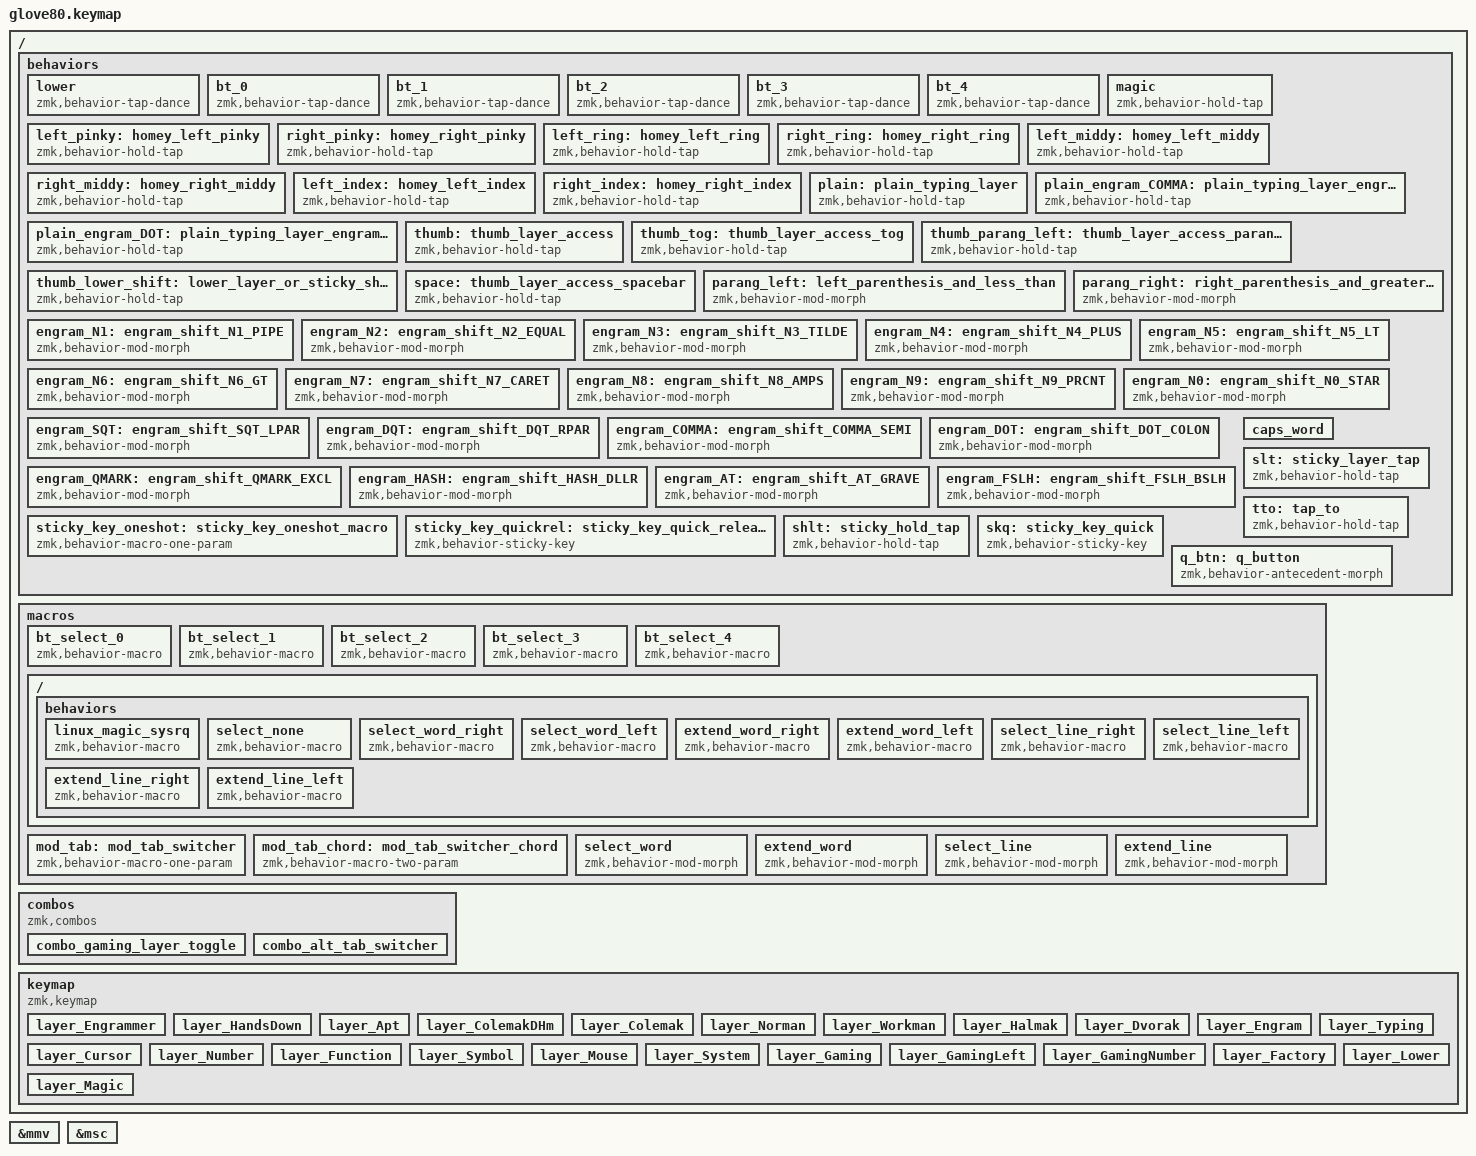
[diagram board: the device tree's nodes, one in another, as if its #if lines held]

/*
 * Copyright (c) 2020 The ZMK Contributors
 * Copyright (c) 2023 Innaworks Development Limited, trading as MoErgo
 *
 * SPDX-License-Identifier: MIT
 */


/* THIS FILE WAS GENERATED BY GLOVE80 LAYOUT EDITOR
 *
 * This file was generated automatically. You may or may not want to
 * edit it directly.
 */

#include <behaviors.dtsi>
/* Include all behavior includes needed */
#include <dt-bindings/zmk/outputs.h>
#include <dt-bindings/zmk/keys.h>
#include <dt-bindings/zmk/bt.h>
#include <dt-bindings/zmk/rgb.h>

/* Automatically generated layer name #define */
#define LAYER_Engrammer 0
#define LAYER_HandsDown 1
#define LAYER_Apt 2
#define LAYER_ColemakDHm 3
#define LAYER_Colemak 4
#define LAYER_Norman 5
#define LAYER_Workman 6
#define LAYER_Halmak 7
#define LAYER_Dvorak 8
#define LAYER_Engram 9
#define LAYER_Typing 10
#define LAYER_Cursor 11
#define LAYER_Number 12
#define LAYER_Function 13
#define LAYER_Symbol 14
#define LAYER_Mouse 15
#define LAYER_System 16
#define LAYER_Gaming 17
#define LAYER_GamingLeft 18
#define LAYER_GamingNumber 19
#define LAYER_Factory 20
#define LAYER_Lower 21
#define LAYER_Magic 22

/* To deal with the situation where there is no Lower layer, to keep &lower happy */
#ifndef LAYER_Lower
#define LAYER_Lower 0
#endif

/* Custom Device-tree */



/* Glove80 system behavior & macros */
/ {
    behaviors {
        // For the "layer" key, it'd nice to be able to use it as either a shift or a toggle.
        // Configure it as a tap dance, so the first tap (or hold) is a &mo and the second tap is a &to
        lower: lower {
            compatible = "zmk,behavior-tap-dance";
            label = "LAYER_TAP_DANCE";
            #binding-cells = <0>;
            tapping-term-ms = <200>;
            bindings = <&mo LAYER_Lower>, <&to LAYER_Lower>;
        };
    };
};

/ {
#ifdef BT_DISC_CMD
    behaviors {
        bt_0: bt_0 {
            compatible = "zmk,behavior-tap-dance";
            label = "BT_0";
            #binding-cells = <0>;
            tapping-term-ms = <200>;
            bindings = <&bt_select_0>, <&bt BT_DISC 0>;
        };
        bt_1: bt_1 {
            compatible = "zmk,behavior-tap-dance";
            label = "BT_1";
            #binding-cells = <0>;
            tapping-term-ms = <200>;
            bindings = <&bt_select_1>, <&bt BT_DISC 1>;
        };
        bt_2: bt_2 {
            compatible = "zmk,behavior-tap-dance";
            label = "BT_2";
            #binding-cells = <0>;
            tapping-term-ms = <200>;
            bindings = <&bt_select_2>, <&bt BT_DISC 2>;
        };
        bt_3: bt_3 {
            compatible = "zmk,behavior-tap-dance";
            label = "BT_3";
            #binding-cells = <0>;
            tapping-term-ms = <200>;
            bindings = <&bt_select_3>, <&bt BT_DISC 3>;
        };
        bt_4: bt_4 {
            compatible = "zmk,behavior-tap-dance";
            label = "BT_4";
            #binding-cells = <0>;
            tapping-term-ms = <200>;
            bindings = <&bt_select_4>, <&bt BT_DISC 4>;
        };
    };
    macros {
        bt_select_0: bt_select_0 {
            label = "BT_SELECT_0";
            compatible = "zmk,behavior-macro";
            #binding-cells = <0>;
            bindings
                = <&out OUT_BLE>,
                  <&bt BT_SEL 0>;
        };
        bt_select_1: bt_select_1 {
            label = "BT_SELECT_1";
            compatible = "zmk,behavior-macro";
            #binding-cells = <0>;
            bindings
                = <&out OUT_BLE>,
                  <&bt BT_SEL 1>;
        };
        bt_select_2: bt_select_2 {
            label = "BT_SELECT_2";
            compatible = "zmk,behavior-macro";
            #binding-cells = <0>;
            bindings
                = <&out OUT_BLE>,
                  <&bt BT_SEL 2>;
        };
        bt_select_3: bt_select_3 {
            label = "BT_SELECT_3";
            compatible = "zmk,behavior-macro";
            #binding-cells = <0>;
            bindings
                = <&out OUT_BLE>,
                  <&bt BT_SEL 3>;
        };
        bt_select_4: bt_select_4 {
            label = "BT_SELECT_4";
            compatible = "zmk,behavior-macro";
            #binding-cells = <0>;
            bindings
                = <&out OUT_BLE>,
                  <&bt BT_SEL 4>;
        };
    };
#else
    macros {
        bt_0: bt_0 {
            label = "BT_0";
            compatible = "zmk,behavior-macro";
            #binding-cells = <0>;
            bindings
                = <&out OUT_BLE>,
                  <&bt BT_SEL 0>;
        };
        bt_1: bt_1 {
            label = "BT_1";
            compatible = "zmk,behavior-macro";
            #binding-cells = <0>;
            bindings
                = <&out OUT_BLE>,
                  <&bt BT_SEL 1>;
        };
        bt_2: bt_2 {
            label = "BT_2";
            compatible = "zmk,behavior-macro";
            #binding-cells = <0>;
            bindings
                = <&out OUT_BLE>,
                  <&bt BT_SEL 2>;
        };
        bt_3: bt_3 {
            label = "BT_3";
            compatible = "zmk,behavior-macro";
            #binding-cells = <0>;
            bindings
                = <&out OUT_BLE>,
                  <&bt BT_SEL 3>;
        };
        bt_4: bt_4 {
            label = "BT_4";
            compatible = "zmk,behavior-macro";
            #binding-cells = <0>;
            bindings
                = <&out OUT_BLE>,
                  <&bt BT_SEL 4>;
        };
    };
#endif
};

/ {
    behaviors {
        magic: magic {
            compatible = "zmk,behavior-hold-tap";
            label = "MAGIC_HOLD_TAP";
            #binding-cells = <2>;
            flavor = "tap-preferred";
            tapping-term-ms = <200>;
            bindings = <&mo>, <&rgb_stat>;
        };
    };
};

/* #define for key positions */
#define POS_LH_T1 52
#define POS_LH_T2 53
#define POS_LH_T3 54
#define POS_LH_T4 69
#define POS_LH_T5 70
#define POS_LH_T6 71
#define POS_LH_C1R2 15
#define POS_LH_C1R3 27
#define POS_LH_C1R4 39
#define POS_LH_C1R5 51
#define POS_LH_C2R1 4
#define POS_LH_C2R2 14
#define POS_LH_C2R3 26
#define POS_LH_C2R4 38
#define POS_LH_C2R5 50
#define POS_LH_C2R6 68
#define POS_LH_C3R1 3
#define POS_LH_C3R2 13
#define POS_LH_C3R3 25
#define POS_LH_C3R4 37
#define POS_LH_C3R5 49
#define POS_LH_C3R6 67
#define POS_LH_C4R1 2
#define POS_LH_C4R2 12
#define POS_LH_C4R3 24
#define POS_LH_C4R4 36
#define POS_LH_C4R5 48
#define POS_LH_C4R6 66
#define POS_LH_C5R1 1
#define POS_LH_C5R2 11
#define POS_LH_C5R3 23
#define POS_LH_C5R4 35
#define POS_LH_C5R5 47
#define POS_LH_C5R6 65
#define POS_LH_C6R1 0
#define POS_LH_C6R2 10
#define POS_LH_C6R3 22
#define POS_LH_C6R4 34
#define POS_LH_C6R5 46
#define POS_LH_C6R6 64
#define POS_RH_T1 57
#define POS_RH_T2 56
#define POS_RH_T3 55
#define POS_RH_T4 74
#define POS_RH_T5 73
#define POS_RH_T6 72
#define POS_RH_C1R2 16
#define POS_RH_C1R3 28
#define POS_RH_C1R4 40
#define POS_RH_C1R5 58
#define POS_RH_C2R1 5
#define POS_RH_C2R2 17
#define POS_RH_C2R3 29
#define POS_RH_C2R4 41
#define POS_RH_C2R5 59
#define POS_RH_C2R6 75
#define POS_RH_C3R1 6
#define POS_RH_C3R2 18
#define POS_RH_C3R3 30
#define POS_RH_C3R4 42
#define POS_RH_C3R5 60
#define POS_RH_C3R6 76
#define POS_RH_C4R1 7
#define POS_RH_C4R2 19
#define POS_RH_C4R3 31
#define POS_RH_C4R4 43
#define POS_RH_C4R5 61
#define POS_RH_C4R6 77
#define POS_RH_C5R1 8
#define POS_RH_C5R2 20
#define POS_RH_C5R3 32
#define POS_RH_C5R4 44
#define POS_RH_C5R5 62
#define POS_RH_C5R6 78
#define POS_RH_C6R1 9
#define POS_RH_C6R2 21
#define POS_RH_C6R3 33
#define POS_RH_C6R4 45
#define POS_RH_C6R5 63
#define POS_RH_C6R6 79

/* Custom Defined Behaviors */
/ {
// Custom settings
//#define OPERATING_SYSTEM 'L' // Linux
//#define OPERATING_SYSTEM 'M' // macOS
#define OPERATING_SYSTEM 'W' // Windows
#define DIFFICULTY_LEVEL  0 // 0:custom, 1:easy -> 5:hard (see below)
//#define WORLD_USE_COMPOSE   // use native Compose in place of Unicode
//#define USE_NUMPAD_KEYCODES // use numpad keys for number layer
#define QU_RESET_TIME 250
#define COMBO_HOLDING_TIME 200
#define LEFT_PINKY_MOD  LGUI
#define RIGHT_PINKY_MOD RGUI
#define LEFT_RING_MOD  LALT
#define RIGHT_RING_MOD RALT
#define LEFT_MIDDY_MOD  LCTL
#define RIGHT_MIDDY_MOD RCTL
#define LEFT_INDEX_MOD  LSFT
#define RIGHT_INDEX_MOD RSFT

// NOTE: Use the `#define` settings below to customize this keymap!
// For example, here are the main optional features you can enable:
//#define DIFFICULTY_LEVEL  0 // 0:custom, 1:easy -> 5:hard (see below)
//#define WORLD_USE_COMPOSE   // use native Compose in place of Unicode
//#define USE_BILATERAL_HOLD_TAPS // use bilateral HRMs in the compiled default keymap
// TIP: Add more setting overrides here instead of editing them below.

//////////////////////////////////////////////////////////////////////////////
//
// Sunaku's Keymap v36 -- "Glorious Engrammer"
// - https://github.com/sunaku/glove80-keymaps
//
//////////////////////////////////////////////////////////////////////////////

//
// DIFFICULTY_LEVEL specifies your level of expertise with this keymap.
// It's meant to help newcomers gradually work their way up to mastery.
// You can disable this setting by omitting it or assigning a `0` zero.
//
// #define DIFFICULTY_LEVEL 0 // custom (see defaults below)
// #define DIFFICULTY_LEVEL 1 // novice (500ms)
// #define DIFFICULTY_LEVEL 2 // slower (400ms)
// #define DIFFICULTY_LEVEL 3 // normal (300ms)
// #define DIFFICULTY_LEVEL 4 // faster (200ms)
// #define DIFFICULTY_LEVEL 5 // expert (100ms)
//
#if defined(DIFFICULTY_LEVEL) && DIFFICULTY_LEVEL > 0
#define DIFFICULTY_LEVEL_HOLDING_TIME  ((6 - DIFFICULTY_LEVEL) * 100)
#define DIFFICULTY_LEVEL_STREAK_DECAY (((6 - DIFFICULTY_LEVEL) *  50) + 100)
#ifndef HOMEY_HOLDING_TIME
#define HOMEY_HOLDING_TIME DIFFICULTY_LEVEL_HOLDING_TIME
#endif
#ifndef HOMEY_STREAK_DECAY
#define HOMEY_STREAK_DECAY DIFFICULTY_LEVEL_STREAK_DECAY
#endif
#ifndef INDEX_HOLDING_TIME
#define INDEX_HOLDING_TIME DIFFICULTY_LEVEL_HOLDING_TIME
#endif
#ifndef INDEX_STREAK_DECAY
#define INDEX_STREAK_DECAY DIFFICULTY_LEVEL_STREAK_DECAY
#endif
#ifndef PLAIN_HOLDING_TIME
#define PLAIN_HOLDING_TIME DIFFICULTY_LEVEL_HOLDING_TIME
#endif
#ifndef PLAIN_STREAK_DECAY
#define PLAIN_STREAK_DECAY DIFFICULTY_LEVEL_STREAK_DECAY
#endif
#ifndef SPACE_HOLDING_TIME
#define SPACE_HOLDING_TIME DIFFICULTY_LEVEL_HOLDING_TIME
#endif
#ifndef SPACE_STREAK_DECAY
#define SPACE_STREAK_DECAY DIFFICULTY_LEVEL_STREAK_DECAY
#endif
#endif

//
// OPERATING_SYSTEM defines which operating system you intend to use
// with this keymap, because shortcuts vary across operating systems.
//
// - https://zmk.dev/docs/codes
// - https://en.wikipedia.org/wiki/Table_of_keyboard_shortcuts
//
#ifndef OPERATING_SYSTEM
//#define OPERATING_SYSTEM 'L' // linux
//#define OPERATING_SYSTEM 'M' // macos
#define OPERATING_SYSTEM 'W' // windows
#endif
#if OPERATING_SYSTEM == 'M'
    #define _C      LG
    #define _A_TAB  LGUI
    #define _G_TAB  LALT
    #define _REDO   _C(LS(Z))
    #define _W      LA
    #define _HOME   _C(LEFT)
    #define _END    _C(RIGHT)
    #define _LOCK   _C(LC(Q))
    #define _SLEEP  C_SLEEP
    #define _POWER  K_POWER
#else
    #define _C      LC
    #define _A_TAB  LALT
    #define _G_TAB  LGUI
    #define _REDO   _C(Y)
    #define _W      _C
    #define _HOME   HOME
    #define _END    END
    #define _LOCK   LG(L)
    #define _SLEEP  SYS_SLEEP
    #define _POWER  SYS_PWR
#endif
/*
#if OPERATING_SYSTEM == 'W'
    #define _LOCK   LG(L)
    #define _SLEEP  SYS_SLEEP
    #define _POWER  SYS_PWR
#elif OPERATING_SYSTEM == 'M'
    #define _LOCK   _C(LC(Q))
    #define _SLEEP  C_SLEEP
    #define _POWER  K_POWER
#elif OPERATING_SYSTEM == 'L'
    #define _LOCK   LG(L)
    #define _SLEEP  C_SLEEP
    #define _POWER  C_POWER
#endif
*/
#define _UNDO       _C(Z)
#define _CUT        _C(X)
#define _COPY       _C(C)
#define _PASTE      _C(V)
#define _FIND       _C(F)
#define _FIND_NEXT  _C(G)
#define _FIND_PREV  _C(LS(G))
#define SLEEP  kp _SLEEP
#define POWER  kp _POWER

//
// USE_NUMPAD_KEYCODES puts `KP_*` keycodes into the Number layer.
//
#ifdef USE_NUMPAD_KEYCODES
#define _KP_N0 KP_N0
#define _KP_N1 KP_N1
#define _KP_N2 KP_N2
#define _KP_N3 KP_N3
#define _KP_N4 KP_N4
#define _KP_N5 KP_N5
#define _KP_N6 KP_N6
#define _KP_N7 KP_N7
#define _KP_N8 KP_N8
#define _KP_N9 KP_N9
#define _KP_PLUS KP_PLUS
#define _KP_MINUS KP_MINUS
#define _KP_ASTERISK KP_ASTERISK
#define _KP_SLASH KP_SLASH
#define _KP_COMMA KP_COMMA
#define _KP_DOT KP_DOT
#define _KP_EQUAL KP_EQUAL
#define _KP_ENTER KP_ENTER
#else
#define _KP_N0 N0
#define _KP_N1 N1
#define _KP_N2 N2
#define _KP_N3 N3
#define _KP_N4 N4
#define _KP_N5 N5
#define _KP_N6 N6
#define _KP_N7 N7
#define _KP_N8 N8
#define _KP_N9 N9
#define _KP_PLUS PLUS
#define _KP_MINUS MINUS
#define _KP_ASTERISK ASTERISK
#define _KP_SLASH SLASH
#define _KP_COMMA COMMA
#define _KP_DOT DOT
#define _KP_EQUAL EQUAL
#define _KP_ENTER ENTER
#endif

//
// Glove80 specific symbol overrides to support non "en-US" locales
//
#undef  AMPS
#define AMPS  LS(N7)
#undef  AT
#define AT    LS(N2)
#undef  CARET
#define CARET LS(N6)
#undef  COLON
#define COLON LS(SEMI)
#undef  DLLR
#define DLLR  LS(N4)
#undef  DQT
#define DQT   LS(SQT)
#undef  EXCL
#define EXCL  LS(N1)
#undef  GT
#define GT    LS(DOT)
#undef  HASH
#define HASH  LS(N3)
#undef  LBRC
#define LBRC  LS(LBKT)
#undef  LPAR
#define LPAR  LS(N9)
#undef  LT
#define LT    LS(COMMA)
#undef  PIPE
#define PIPE  LS(BSLH)
#undef  PLUS
#define PLUS  LS(EQUAL)
#undef  PRCNT
#define PRCNT LS(N5)
#undef  QMARK
#define QMARK LS(FSLH)
#undef  RBRC
#define RBRC  LS(RBKT)
#undef  RPAR
#define RPAR  LS(N0)
#undef  STAR
#define STAR  LS(N8)
#undef  TILDE
#define TILDE LS(GRAVE)
#undef  UNDER
#define UNDER LS(MINUS)

//
// Keymap specific knowledge of the base layer's alpha + ZMK layout
//
#if defined(LAYER_Engrammer) && LAYER_Engrammer == 0
#define KEY_LH_C6R1 F1
#define KEY_LH_C5R1 F2
#define KEY_LH_C4R1 F3
#define KEY_LH_C3R1 F4
#define KEY_LH_C2R1 F5
#define KEY_RH_C2R1 F6
#define KEY_RH_C3R1 F7
#define KEY_RH_C4R1 F8
#define KEY_RH_C5R1 F9
#define KEY_RH_C6R1 F10
#define KEY_LH_C6R2 GRAVE
#define KEY_LH_C5R2 N1
#define KEY_LH_C4R2 N2
#define KEY_LH_C3R2 N3
#define KEY_LH_C2R2 N4
#define KEY_LH_C1R2 N5
#define KEY_RH_C1R2 N6
#define KEY_RH_C2R2 N7
#define KEY_RH_C3R2 N8
#define KEY_RH_C4R2 N9
#define KEY_RH_C5R2 N0
#define KEY_RH_C6R2 BSLH
#define KEY_LH_C6R3 EQUAL
#define KEY_LH_C5R3 B
#define KEY_LH_C4R3 Y
#define KEY_LH_C3R3 O
#define KEY_LH_C2R3 U
#define KEY_LH_C1R3 SQT
#define KEY_RH_C1R3 SEMI
#define KEY_RH_C2R3 L
#define KEY_RH_C3R3 D
#define KEY_RH_C4R3 W
#define KEY_RH_C5R3 V
#define KEY_RH_C6R3 Z
#define KEY_LH_C6R4 0
#define KEY_LH_C5R4 C
#define KEY_LH_C4R4 I
#define KEY_LH_C3R4 E
#define KEY_LH_C2R4 A
#define KEY_LH_C1R4 COMMA
#define KEY_RH_C1R4 DOT
#define KEY_RH_C2R4 H
#define KEY_RH_C3R4 T
#define KEY_RH_C4R4 S
#define KEY_RH_C5R4 N
#define KEY_RH_C6R4 Q
#define KEY_LH_C6R5 LSHFT
#define KEY_LH_C5R5 G
#define KEY_LH_C4R5 X
#define KEY_LH_C3R5 J
#define KEY_LH_C2R5 K
#define KEY_LH_C1R5 MINUS
#define KEY_LH_T1 ESC
#define KEY_LH_T2 UP
#define KEY_LH_T3 DOWN
#define KEY_RH_T3 LEFT
#define KEY_RH_T2 RIGHT
#define KEY_RH_T1 ENTER
#define KEY_RH_C1R5 FSLH
#define KEY_RH_C2R5 R
#define KEY_RH_C3R5 M
#define KEY_RH_C4R5 F
#define KEY_RH_C5R5 P
#define KEY_RH_C6R5 RSHFT
#define KEY_LH_C6R6 0
#define KEY_LH_C5R6 HOME
#define KEY_LH_C4R6 PG_UP
#define KEY_LH_C3R6 PG_DN
#define KEY_LH_C2R6 END
#define KEY_LH_T4 BACKSPACE
#define KEY_LH_T5 LSFT
#define KEY_LH_T6 DELETE
#define KEY_RH_T6 TAB
#define KEY_RH_T5 RSFT
#define KEY_RH_T4 SPACE
#define KEY_RH_C2R6 LPAR
#define KEY_RH_C3R6 LBKT
#define KEY_RH_C4R6 RBKT
#define KEY_RH_C5R6 RPAR
#define KEY_RH_C6R6 0
#endif
#if defined(LAYER_Engram) && LAYER_Engram == 0
#define KEY_LH_C6R1 F1
#define KEY_LH_C5R1 F2
#define KEY_LH_C4R1 F3
#define KEY_LH_C3R1 F4
#define KEY_LH_C2R1 F5
#define KEY_RH_C2R1 F6
#define KEY_RH_C3R1 F7
#define KEY_RH_C4R1 F8
#define KEY_RH_C5R1 F9
#define KEY_RH_C6R1 F10
#define KEY_LH_C6R2 LBKT
#define KEY_LH_C5R2 N1
#define KEY_LH_C4R2 N2
#define KEY_LH_C3R2 N3
#define KEY_LH_C2R2 N4
#define KEY_LH_C1R2 N5
#define KEY_RH_C1R2 N6
#define KEY_RH_C2R2 N7
#define KEY_RH_C3R2 N8
#define KEY_RH_C4R2 N9
#define KEY_RH_C5R2 N0
#define KEY_RH_C6R2 RBKT
#define KEY_LH_C6R3 AT
#define KEY_LH_C5R3 B
#define KEY_LH_C4R3 Y
#define KEY_LH_C3R3 O
#define KEY_LH_C2R3 U
#define KEY_LH_C1R3 SQT
#define KEY_RH_C1R3 DQT
#define KEY_RH_C2R3 L
#define KEY_RH_C3R3 D
#define KEY_RH_C4R3 W
#define KEY_RH_C5R3 V
#define KEY_RH_C6R3 Z
#define KEY_LH_C6R4 0
#define KEY_LH_C5R4 C
#define KEY_LH_C4R4 I
#define KEY_LH_C3R4 E
#define KEY_LH_C2R4 A
#define KEY_LH_C1R4 COMMA
#define KEY_RH_C1R4 DOT
#define KEY_RH_C2R4 H
#define KEY_RH_C3R4 T
#define KEY_RH_C4R4 S
#define KEY_RH_C5R4 N
#define KEY_RH_C6R4 Q
#define KEY_LH_C6R5 LSHFT
#define KEY_LH_C5R5 G
#define KEY_LH_C4R5 X
#define KEY_LH_C3R5 J
#define KEY_LH_C2R5 K
#define KEY_LH_C1R5 MINUS
#define KEY_LH_T1 ESC
#define KEY_LH_T2 UP
#define KEY_LH_T3 DOWN
#define KEY_RH_T3 LEFT
#define KEY_RH_T2 RIGHT
#define KEY_RH_T1 ENTER
#define KEY_RH_C1R5 QMARK
#define KEY_RH_C2R5 R
#define KEY_RH_C3R5 M
#define KEY_RH_C4R5 F
#define KEY_RH_C5R5 P
#define KEY_RH_C6R5 RSHFT
#define KEY_LH_C6R6 0
#define KEY_LH_C5R6 HOME
#define KEY_LH_C4R6 PG_UP
#define KEY_LH_C3R6 PG_DN
#define KEY_LH_C2R6 END
#define KEY_LH_T4 BACKSPACE
#define KEY_LH_T5 LSFT
#define KEY_LH_T6 DELETE
#define KEY_RH_T6 TAB
#define KEY_RH_T5 RSFT
#define KEY_RH_T4 SPACE
#define KEY_RH_C2R6 LPAR
#define KEY_RH_C3R6 HASH
#define KEY_RH_C4R6 FSLH
#define KEY_RH_C5R6 RPAR
#define KEY_RH_C6R6 0
#endif
#if defined(LAYER_Dvorak) && LAYER_Dvorak == 0
#define KEY_LH_C6R1 F1
#define KEY_LH_C5R1 F2
#define KEY_LH_C4R1 F3
#define KEY_LH_C3R1 F4
#define KEY_LH_C2R1 F5
#define KEY_RH_C2R1 F6
#define KEY_RH_C3R1 F7
#define KEY_RH_C4R1 F8
#define KEY_RH_C5R1 F9
#define KEY_RH_C6R1 F10
#define KEY_LH_C6R2 GRAVE
#define KEY_LH_C5R2 N1
#define KEY_LH_C4R2 N2
#define KEY_LH_C3R2 N3
#define KEY_LH_C2R2 N4
#define KEY_LH_C1R2 N5
#define KEY_RH_C1R2 N6
#define KEY_RH_C2R2 N7
#define KEY_RH_C3R2 N8
#define KEY_RH_C4R2 N9
#define KEY_RH_C5R2 N0
#define KEY_RH_C6R2 BSLH
#define KEY_LH_C6R3 EQUAL
#define KEY_LH_C5R3 SQT
#define KEY_LH_C4R3 COMMA
#define KEY_LH_C3R3 DOT
#define KEY_LH_C2R3 P
#define KEY_LH_C1R3 Y
#define KEY_RH_C1R3 F
#define KEY_RH_C2R3 G
#define KEY_RH_C3R3 C
#define KEY_RH_C4R3 R
#define KEY_RH_C5R3 L
#define KEY_RH_C6R3 SLASH
#define KEY_LH_C6R4 0
#define KEY_LH_C5R4 A
#define KEY_LH_C4R4 O
#define KEY_LH_C3R4 E
#define KEY_LH_C2R4 U
#define KEY_LH_C1R4 I
#define KEY_RH_C1R4 D
#define KEY_RH_C2R4 H
#define KEY_RH_C3R4 T
#define KEY_RH_C4R4 N
#define KEY_RH_C5R4 S
#define KEY_RH_C6R4 MINUS
#define KEY_LH_C6R5 LSHFT
#define KEY_LH_C5R5 SEMI
#define KEY_LH_C4R5 Q
#define KEY_LH_C3R5 J
#define KEY_LH_C2R5 K
#define KEY_LH_C1R5 X
#define KEY_LH_T1 ESC
#define KEY_LH_T2 UP
#define KEY_LH_T3 DOWN
#define KEY_RH_T3 LEFT
#define KEY_RH_T2 RIGHT
#define KEY_RH_T1 ENTER
#define KEY_RH_C1R5 B
#define KEY_RH_C2R5 M
#define KEY_RH_C3R5 W
#define KEY_RH_C4R5 V
#define KEY_RH_C5R5 Z
#define KEY_RH_C6R5 RSHFT
#define KEY_LH_C6R6 0
#define KEY_LH_C5R6 HOME
#define KEY_LH_C4R6 PG_UP
#define KEY_LH_C3R6 PG_DN
#define KEY_LH_C2R6 END
#define KEY_LH_T4 BACKSPACE
#define KEY_LH_T5 LSFT
#define KEY_LH_T6 DELETE
#define KEY_RH_T6 TAB
#define KEY_RH_T5 RSFT
#define KEY_RH_T4 SPACE
#define KEY_RH_C2R6 LPAR
#define KEY_RH_C3R6 LBKT
#define KEY_RH_C4R6 RBKT
#define KEY_RH_C5R6 RPAR
#define KEY_RH_C6R6 0
#endif
#if defined(LAYER_HandsDown) && LAYER_HandsDown == 0
#define KEY_LH_C6R1 F1
#define KEY_LH_C5R1 F2
#define KEY_LH_C4R1 F3
#define KEY_LH_C3R1 F4
#define KEY_LH_C2R1 F5
#define KEY_RH_C2R1 F6
#define KEY_RH_C3R1 F7
#define KEY_RH_C4R1 F8
#define KEY_RH_C5R1 F9
#define KEY_RH_C6R1 F10
#define KEY_LH_C6R2 GRAVE
#define KEY_LH_C5R2 N1
#define KEY_LH_C4R2 N2
#define KEY_LH_C3R2 N3
#define KEY_LH_C2R2 N4
#define KEY_LH_C1R2 N5
#define KEY_RH_C1R2 N6
#define KEY_RH_C2R2 N7
#define KEY_RH_C3R2 N8
#define KEY_RH_C4R2 N9
#define KEY_RH_C5R2 N0
#define KEY_RH_C6R2 UNDER
#define KEY_LH_C6R3 EQUAL
#define KEY_LH_C5R3 X
#define KEY_LH_C4R3 W
#define KEY_LH_C3R3 M
#define KEY_LH_C2R3 G
#define KEY_LH_C1R3 J
#define KEY_RH_C1R3 POUND
#define KEY_RH_C2R3 DOT
#define KEY_RH_C3R3 FSLH
#define KEY_RH_C4R3 DQT
#define KEY_RH_C5R3 SQT
#define KEY_RH_C6R3 Z
#define KEY_LH_C6R4 CAPS
#define KEY_LH_C5R4 S
#define KEY_LH_C4R4 C
#define KEY_LH_C3R4 N
#define KEY_LH_C2R4 T
#define KEY_LH_C1R4 K
#define KEY_RH_C1R4 COMMA
#define KEY_RH_C2R4 A
#define KEY_RH_C3R4 E
#define KEY_RH_C4R4 I
#define KEY_RH_C5R4 H
#define KEY_RH_C6R4 Q
#define KEY_LH_C6R5 LSHFT
#define KEY_LH_C5R5 B
#define KEY_LH_C4R5 F
#define KEY_LH_C3R5 L
#define KEY_LH_C2R5 D
#define KEY_LH_C1R5 V
#define KEY_LH_T1 ESC
#define KEY_LH_T2 UP
#define KEY_LH_T3 DOWN
#define KEY_RH_T3 LEFT
#define KEY_RH_T2 RIGHT
#define KEY_RH_T1 ENTER
#define KEY_RH_C1R5 MINUS
#define KEY_RH_C2R5 U
#define KEY_RH_C3R5 O
#define KEY_RH_C4R5 Y
#define KEY_RH_C5R5 P
#define KEY_RH_C6R5 RSHFT
#define KEY_LH_C6R6 0
#define KEY_LH_C5R6 HOME
#define KEY_LH_C4R6 PG_UP
#define KEY_LH_C3R6 PG_DN
#define KEY_LH_C2R6 END
#define KEY_LH_T4 BACKSPACE
#define KEY_LH_T5 LSFT
#define KEY_LH_T6 DELETE
#define KEY_RH_T6 TAB
#define KEY_RH_T5 RSFT
#define KEY_RH_T4 SPACE
#define KEY_RH_C2R6 LPAR
#define KEY_RH_C3R6 HASH
#define KEY_RH_C4R6 FSLH
#define KEY_RH_C5R6 RPAR
#define KEY_RH_C6R6 0
#endif
#if defined(LAYER_Apt) && LAYER_Apt == 0
#define KEY_LH_C6R1 F1
#define KEY_LH_C5R1 F2
#define KEY_LH_C4R1 F3
#define KEY_LH_C3R1 F4
#define KEY_LH_C2R1 F5
#define KEY_RH_C2R1 F6
#define KEY_RH_C3R1 F7
#define KEY_RH_C4R1 F8
#define KEY_RH_C5R1 F9
#define KEY_RH_C6R1 F10
#define KEY_LH_C6R2 GRAVE
#define KEY_LH_C5R2 N1
#define KEY_LH_C4R2 N2
#define KEY_LH_C3R2 N3
#define KEY_LH_C2R2 N4
#define KEY_LH_C1R2 N5
#define KEY_RH_C1R2 N6
#define KEY_RH_C2R2 N7
#define KEY_RH_C3R2 N8
#define KEY_RH_C4R2 N9
#define KEY_RH_C5R2 N0
#define KEY_RH_C6R2 BSLH
#define KEY_LH_C6R3 EQUAL
#define KEY_LH_C5R3 W
#define KEY_LH_C4R3 G
#define KEY_LH_C3R3 D
#define KEY_LH_C2R3 F
#define KEY_LH_C1R3 B
#define KEY_RH_C1R3 Q
#define KEY_RH_C2R3 L
#define KEY_RH_C3R3 U
#define KEY_RH_C4R3 O
#define KEY_RH_C5R3 Y
#define KEY_RH_C6R3 MINUS
#define KEY_LH_C6R4 0
#define KEY_LH_C5R4 R
#define KEY_LH_C4R4 S
#define KEY_LH_C3R4 T
#define KEY_LH_C2R4 H
#define KEY_LH_C1R4 K
#define KEY_RH_C1R4 J
#define KEY_RH_C2R4 N
#define KEY_RH_C3R4 E
#define KEY_RH_C4R4 A
#define KEY_RH_C5R4 I
#define KEY_RH_C6R4 SEMI
#define KEY_LH_C6R5 LSHFT
#define KEY_LH_C5R5 X
#define KEY_LH_C4R5 C
#define KEY_LH_C3R5 M
#define KEY_LH_C2R5 P
#define KEY_LH_C1R5 V
#define KEY_LH_T1 ESC
#define KEY_LH_T2 UP
#define KEY_LH_T3 DOWN
#define KEY_RH_T3 LEFT
#define KEY_RH_T2 RIGHT
#define KEY_RH_T1 ENTER
#define KEY_RH_C1R5 Z
#define KEY_RH_C2R5 COMMA
#define KEY_RH_C3R5 DOT
#define KEY_RH_C4R5 SQT
#define KEY_RH_C5R5 FSLH
#define KEY_RH_C6R5 RSHFT
#define KEY_LH_C6R6 0
#define KEY_LH_C5R6 HOME
#define KEY_LH_C4R6 PG_UP
#define KEY_LH_C3R6 PG_DN
#define KEY_LH_C2R6 END
#define KEY_LH_T4 BACKSPACE
#define KEY_LH_T5 LSFT
#define KEY_LH_T6 DELETE
#define KEY_RH_T6 TAB
#define KEY_RH_T5 RSFT
#define KEY_RH_T4 SPACE
#define KEY_RH_C2R6 LPAR
#define KEY_RH_C3R6 LBKT
#define KEY_RH_C4R6 RBKT
#define KEY_RH_C5R6 RPAR
#define KEY_RH_C6R6 0
#endif
#if defined(LAYER_ColemakDHm) && LAYER_ColemakDHm == 0
#define KEY_LH_C6R1 F1
#define KEY_LH_C5R1 F2
#define KEY_LH_C4R1 F3
#define KEY_LH_C3R1 F4
#define KEY_LH_C2R1 F5
#define KEY_RH_C2R1 F6
#define KEY_RH_C3R1 F7
#define KEY_RH_C4R1 F8
#define KEY_RH_C5R1 F9
#define KEY_RH_C6R1 F10
#define KEY_LH_C6R2 GRAVE
#define KEY_LH_C5R2 N1
#define KEY_LH_C4R2 N2
#define KEY_LH_C3R2 N3
#define KEY_LH_C2R2 N4
#define KEY_LH_C1R2 N5
#define KEY_RH_C1R2 N6
#define KEY_RH_C2R2 N7
#define KEY_RH_C3R2 N8
#define KEY_RH_C4R2 N9
#define KEY_RH_C5R2 N0
#define KEY_RH_C6R2 BSLH
#define KEY_LH_C6R3 EQUAL
#define KEY_LH_C5R3 Q
#define KEY_LH_C4R3 W
#define KEY_LH_C3R3 F
#define KEY_LH_C2R3 P
#define KEY_LH_C1R3 B
#define KEY_RH_C1R3 J
#define KEY_RH_C2R3 L
#define KEY_RH_C3R3 U
#define KEY_RH_C4R3 Y
#define KEY_RH_C5R3 SEMI
#define KEY_RH_C6R3 MINUS
#define KEY_LH_C6R4 0
#define KEY_LH_C5R4 A
#define KEY_LH_C4R4 R
#define KEY_LH_C3R4 S
#define KEY_LH_C2R4 T
#define KEY_LH_C1R4 G
#define KEY_RH_C1R4 M
#define KEY_RH_C2R4 N
#define KEY_RH_C3R4 E
#define KEY_RH_C4R4 I
#define KEY_RH_C5R4 O
#define KEY_RH_C6R4 SQT
#define KEY_LH_C6R5 LSHFT
#define KEY_LH_C5R5 Z
#define KEY_LH_C4R5 X
#define KEY_LH_C3R5 C
#define KEY_LH_C2R5 D
#define KEY_LH_C1R5 V
#define KEY_LH_T1 ESC
#define KEY_LH_T2 UP
#define KEY_LH_T3 DOWN
#define KEY_RH_T3 LEFT
#define KEY_RH_T2 RIGHT
#define KEY_RH_T1 ENTER
#define KEY_RH_C1R5 K
#define KEY_RH_C2R5 H
#define KEY_RH_C3R5 COMMA
#define KEY_RH_C4R5 DOT
#define KEY_RH_C5R5 FSLH
#define KEY_RH_C6R5 RSHFT
#define KEY_LH_C6R6 0
#define KEY_LH_C5R6 HOME
#define KEY_LH_C4R6 PG_UP
#define KEY_LH_C3R6 PG_DN
#define KEY_LH_C2R6 END
#define KEY_LH_T4 BACKSPACE
#define KEY_LH_T5 LSFT
#define KEY_LH_T6 DELETE
#define KEY_RH_T6 TAB
#define KEY_RH_T5 RSFT
#define KEY_RH_T4 SPACE
#define KEY_RH_C2R6 LPAR
#define KEY_RH_C3R6 LBKT
#define KEY_RH_C4R6 RBKT
#define KEY_RH_C5R6 RPAR
#define KEY_RH_C6R6 0
#endif
#if defined(LAYER_Colemak) && LAYER_Colemak == 0
#define KEY_LH_C6R1 F1
#define KEY_LH_C5R1 F2
#define KEY_LH_C4R1 F3
#define KEY_LH_C3R1 F4
#define KEY_LH_C2R1 F5
#define KEY_RH_C2R1 F6
#define KEY_RH_C3R1 F7
#define KEY_RH_C4R1 F8
#define KEY_RH_C5R1 F9
#define KEY_RH_C6R1 F10
#define KEY_LH_C6R2 GRAVE
#define KEY_LH_C5R2 N1
#define KEY_LH_C4R2 N2
#define KEY_LH_C3R2 N3
#define KEY_LH_C2R2 N4
#define KEY_LH_C1R2 N5
#define KEY_RH_C1R2 N6
#define KEY_RH_C2R2 N7
#define KEY_RH_C3R2 N8
#define KEY_RH_C4R2 N9
#define KEY_RH_C5R2 N0
#define KEY_RH_C6R2 BSLH
#define KEY_LH_C6R3 EQUAL
#define KEY_LH_C5R3 Q
#define KEY_LH_C4R3 W
#define KEY_LH_C3R3 F
#define KEY_LH_C2R3 P
#define KEY_LH_C1R3 G
#define KEY_RH_C1R3 J
#define KEY_RH_C2R3 L
#define KEY_RH_C3R3 U
#define KEY_RH_C4R3 Y
#define KEY_RH_C5R3 SEMI
#define KEY_RH_C6R3 MINUS
#define KEY_LH_C6R4 0
#define KEY_LH_C5R4 A
#define KEY_LH_C4R4 R
#define KEY_LH_C3R4 S
#define KEY_LH_C2R4 T
#define KEY_LH_C1R4 D
#define KEY_RH_C1R4 H
#define KEY_RH_C2R4 N
#define KEY_RH_C3R4 E
#define KEY_RH_C4R4 I
#define KEY_RH_C5R4 O
#define KEY_RH_C6R4 SQT
#define KEY_LH_C6R5 LSHFT
#define KEY_LH_C5R5 Z
#define KEY_LH_C4R5 X
#define KEY_LH_C3R5 C
#define KEY_LH_C2R5 V
#define KEY_LH_C1R5 B
#define KEY_LH_T1 ESC
#define KEY_LH_T2 UP
#define KEY_LH_T3 DOWN
#define KEY_RH_T3 LEFT
#define KEY_RH_T2 RIGHT
#define KEY_RH_T1 ENTER
#define KEY_RH_C1R5 K
#define KEY_RH_C2R5 M
#define KEY_RH_C3R5 COMMA
#define KEY_RH_C4R5 DOT
#define KEY_RH_C5R5 FSLH
#define KEY_RH_C6R5 RSHFT
#define KEY_LH_C6R6 0
#define KEY_LH_C5R6 HOME
#define KEY_LH_C4R6 PG_UP
#define KEY_LH_C3R6 PG_DN
#define KEY_LH_C2R6 END
#define KEY_LH_T4 BACKSPACE
#define KEY_LH_T5 LSFT
#define KEY_LH_T6 DELETE
#define KEY_RH_T6 TAB
#define KEY_RH_T5 RSFT
#define KEY_RH_T4 SPACE
#define KEY_RH_C2R6 LPAR
#define KEY_RH_C3R6 LBKT
#define KEY_RH_C4R6 RBKT
#define KEY_RH_C5R6 RPAR
#define KEY_RH_C6R6 0
#endif
#if defined(LAYER_QWERTY) && LAYER_QWERTY == 0
#define KEY_LH_C6R1 F1
#define KEY_LH_C5R1 F2
#define KEY_LH_C4R1 F3
#define KEY_LH_C3R1 F4
#define KEY_LH_C2R1 F5
#define KEY_RH_C2R1 F6
#define KEY_RH_C3R1 F7
#define KEY_RH_C4R1 F8
#define KEY_RH_C5R1 F9
#define KEY_RH_C6R1 F10
#define KEY_LH_C6R2 GRAVE
#define KEY_LH_C5R2 N1
#define KEY_LH_C4R2 N2
#define KEY_LH_C3R2 N3
#define KEY_LH_C2R2 N4
#define KEY_LH_C1R2 N5
#define KEY_RH_C1R2 N6
#define KEY_RH_C2R2 N7
#define KEY_RH_C3R2 N8
#define KEY_RH_C4R2 N9
#define KEY_RH_C5R2 N0
#define KEY_RH_C6R2 BSLH
#define KEY_LH_C6R3 EQUAL
#define KEY_LH_C5R3 Q
#define KEY_LH_C4R3 W
#define KEY_LH_C3R3 E
#define KEY_LH_C2R3 R
#define KEY_LH_C1R3 T
#define KEY_RH_C1R3 Y
#define KEY_RH_C2R3 U
#define KEY_RH_C3R3 I
#define KEY_RH_C4R3 O
#define KEY_RH_C5R3 P
#define KEY_RH_C6R3 MINUS
#define KEY_LH_C6R4 0
#define KEY_LH_C5R4 A
#define KEY_LH_C4R4 S
#define KEY_LH_C3R4 D
#define KEY_LH_C2R4 F
#define KEY_LH_C1R4 G
#define KEY_RH_C1R4 H
#define KEY_RH_C2R4 J
#define KEY_RH_C3R4 K
#define KEY_RH_C4R4 L
#define KEY_RH_C5R4 SEMI
#define KEY_RH_C6R4 SQT
#define KEY_LH_C6R5 LSHFT
#define KEY_LH_C5R5 Z
#define KEY_LH_C4R5 X
#define KEY_LH_C3R5 C
#define KEY_LH_C2R5 V
#define KEY_LH_C1R5 B
#define KEY_LH_T1 ESC
#define KEY_LH_T2 UP
#define KEY_LH_T3 DOWN
#define KEY_RH_T3 LEFT
#define KEY_RH_T2 RIGHT
#define KEY_RH_T1 ENTER
#define KEY_RH_C1R5 N
#define KEY_RH_C2R5 M
#define KEY_RH_C3R5 COMMA
#define KEY_RH_C4R5 DOT
#define KEY_RH_C5R5 FSLH
#define KEY_RH_C6R5 RSHFT
#define KEY_LH_C6R6 0
#define KEY_LH_C5R6 HOME
#define KEY_LH_C4R6 PG_UP
#define KEY_LH_C3R6 PG_DN
#define KEY_LH_C2R6 END
#define KEY_LH_T4 BACKSPACE
#define KEY_LH_T5 LSFT
#define KEY_LH_T6 DELETE
#define KEY_RH_T6 TAB
#define KEY_RH_T5 RSFT
#define KEY_RH_T4 SPACE
#define KEY_RH_C2R6 LPAR
#define KEY_RH_C3R6 LBKT
#define KEY_RH_C4R6 RBKT
#define KEY_RH_C5R6 RPAR
#define KEY_RH_C6R6 0
#endif
#if defined(LAYER_Norman) && LAYER_Norman == 0
#define KEY_LH_C6R1 F1
#define KEY_LH_C5R1 F2
#define KEY_LH_C4R1 F3
#define KEY_LH_C3R1 F4
#define KEY_LH_C2R1 F5
#define KEY_RH_C2R1 F6
#define KEY_RH_C3R1 F7
#define KEY_RH_C4R1 F8
#define KEY_RH_C5R1 F9
#define KEY_RH_C6R1 F10
#define KEY_LH_C6R2 GRAVE
#define KEY_LH_C5R2 N1
#define KEY_LH_C4R2 N2
#define KEY_LH_C3R2 N3
#define KEY_LH_C2R2 N4
#define KEY_LH_C1R2 N5
#define KEY_RH_C1R2 N6
#define KEY_RH_C2R2 N7
#define KEY_RH_C3R2 N8
#define KEY_RH_C4R2 N9
#define KEY_RH_C5R2 N0
#define KEY_RH_C6R2 BSLH
#define KEY_LH_C6R3 EQUAL
#define KEY_LH_C5R3 Q
#define KEY_LH_C4R3 W
#define KEY_LH_C3R3 D
#define KEY_LH_C2R3 F
#define KEY_LH_C1R3 K
#define KEY_RH_C1R3 J
#define KEY_RH_C2R3 U
#define KEY_RH_C3R3 R
#define KEY_RH_C4R3 L
#define KEY_RH_C5R3 SEMI
#define KEY_RH_C6R3 MINUS
#define KEY_LH_C6R4 0
#define KEY_LH_C5R4 A
#define KEY_LH_C4R4 S
#define KEY_LH_C3R4 E
#define KEY_LH_C2R4 T
#define KEY_LH_C1R4 G
#define KEY_RH_C1R4 Y
#define KEY_RH_C2R4 N
#define KEY_RH_C3R4 I
#define KEY_RH_C4R4 O
#define KEY_RH_C5R4 H
#define KEY_RH_C6R4 SQT
#define KEY_LH_C6R5 LSHFT
#define KEY_LH_C5R5 Z
#define KEY_LH_C4R5 X
#define KEY_LH_C3R5 C
#define KEY_LH_C2R5 V
#define KEY_LH_C1R5 B
#define KEY_LH_T1 ESC
#define KEY_LH_T2 UP
#define KEY_LH_T3 DOWN
#define KEY_RH_T3 LEFT
#define KEY_RH_T2 RIGHT
#define KEY_RH_T1 ENTER
#define KEY_RH_C1R5 P
#define KEY_RH_C2R5 M
#define KEY_RH_C3R5 COMMA
#define KEY_RH_C4R5 DOT
#define KEY_RH_C5R5 FSLH
#define KEY_RH_C6R5 RSHFT
#define KEY_LH_C6R6 0
#define KEY_LH_C5R6 HOME
#define KEY_LH_C4R6 PG_UP
#define KEY_LH_C3R6 PG_DN
#define KEY_LH_C2R6 END
#define KEY_LH_T4 BACKSPACE
#define KEY_LH_T5 LSFT
#define KEY_LH_T6 DELETE
#define KEY_RH_T6 TAB
#define KEY_RH_T5 RSFT
#define KEY_RH_T4 SPACE
#define KEY_RH_C2R6 LPAR
#define KEY_RH_C3R6 LBKT
#define KEY_RH_C4R6 RBKT
#define KEY_RH_C5R6 RPAR
#define KEY_RH_C6R6 0
#endif
#if defined(LAYER_Workman) && LAYER_Workman == 0
#define KEY_LH_C6R1 F1
#define KEY_LH_C5R1 F2
#define KEY_LH_C4R1 F3
#define KEY_LH_C3R1 F4
#define KEY_LH_C2R1 F5
#define KEY_RH_C2R1 F6
#define KEY_RH_C3R1 F7
#define KEY_RH_C4R1 F8
#define KEY_RH_C5R1 F9
#define KEY_RH_C6R1 F10
#define KEY_LH_C6R2 GRAVE
#define KEY_LH_C5R2 N1
#define KEY_LH_C4R2 N2
#define KEY_LH_C3R2 N3
#define KEY_LH_C2R2 N4
#define KEY_LH_C1R2 N5
#define KEY_RH_C1R2 N6
#define KEY_RH_C2R2 N7
#define KEY_RH_C3R2 N8
#define KEY_RH_C4R2 N9
#define KEY_RH_C5R2 N0
#define KEY_RH_C6R2 BSLH
#define KEY_LH_C6R3 EQUAL
#define KEY_LH_C5R3 Q
#define KEY_LH_C4R3 D
#define KEY_LH_C3R3 R
#define KEY_LH_C2R3 W
#define KEY_LH_C1R3 B
#define KEY_RH_C1R3 J
#define KEY_RH_C2R3 F
#define KEY_RH_C3R3 U
#define KEY_RH_C4R3 P
#define KEY_RH_C5R3 SEMI
#define KEY_RH_C6R3 MINUS
#define KEY_LH_C6R4 0
#define KEY_LH_C5R4 A
#define KEY_LH_C4R4 S
#define KEY_LH_C3R4 H
#define KEY_LH_C2R4 T
#define KEY_LH_C1R4 G
#define KEY_RH_C1R4 Y
#define KEY_RH_C2R4 N
#define KEY_RH_C3R4 E
#define KEY_RH_C4R4 O
#define KEY_RH_C5R4 I
#define KEY_RH_C6R4 SQT
#define KEY_LH_C6R5 LSHFT
#define KEY_LH_C5R5 Z
#define KEY_LH_C4R5 X
#define KEY_LH_C3R5 M
#define KEY_LH_C2R5 C
#define KEY_LH_C1R5 V
#define KEY_LH_T1 ESC
#define KEY_LH_T2 UP
#define KEY_LH_T3 DOWN
#define KEY_RH_T3 LEFT
#define KEY_RH_T2 RIGHT
#define KEY_RH_T1 ENTER
#define KEY_RH_C1R5 K
#define KEY_RH_C2R5 L
#define KEY_RH_C3R5 COMMA
#define KEY_RH_C4R5 DOT
#define KEY_RH_C5R5 FSLH
#define KEY_RH_C6R5 RSHFT
#define KEY_LH_C6R6 0
#define KEY_LH_C5R6 HOME
#define KEY_LH_C4R6 PG_UP
#define KEY_LH_C3R6 PG_DN
#define KEY_LH_C2R6 END
#define KEY_LH_T4 BACKSPACE
#define KEY_LH_T5 LSFT
#define KEY_LH_T6 DELETE
#define KEY_RH_T6 TAB
#define KEY_RH_T5 RSFT
#define KEY_RH_T4 SPACE
#define KEY_RH_C2R6 LPAR
#define KEY_RH_C3R6 LBKT
#define KEY_RH_C4R6 RBKT
#define KEY_RH_C5R6 RPAR
#define KEY_RH_C6R6 0
#endif
#if defined(LAYER_Halmak) && LAYER_Halmak == 0
#define KEY_LH_C6R1 F1
#define KEY_LH_C5R1 F2
#define KEY_LH_C4R1 F3
#define KEY_LH_C3R1 F4
#define KEY_LH_C2R1 F5
#define KEY_RH_C2R1 F6
#define KEY_RH_C3R1 F7
#define KEY_RH_C4R1 F8
#define KEY_RH_C5R1 F9
#define KEY_RH_C6R1 F10
#define KEY_LH_C6R2 GRAVE
#define KEY_LH_C5R2 N1
#define KEY_LH_C4R2 N2
#define KEY_LH_C3R2 N3
#define KEY_LH_C2R2 N4
#define KEY_LH_C1R2 N5
#define KEY_RH_C1R2 N6
#define KEY_RH_C2R2 N7
#define KEY_RH_C3R2 N8
#define KEY_RH_C4R2 N9
#define KEY_RH_C5R2 N0
#define KEY_RH_C6R2 BSLH
#define KEY_LH_C6R3 EQUAL
#define KEY_LH_C5R3 W
#define KEY_LH_C4R3 L
#define KEY_LH_C3R3 R
#define KEY_LH_C2R3 B
#define KEY_LH_C1R3 Z
#define KEY_RH_C1R3 SEMI
#define KEY_RH_C2R3 Q
#define KEY_RH_C3R3 U
#define KEY_RH_C4R3 D
#define KEY_RH_C5R3 J
#define KEY_RH_C6R3 MINUS
#define KEY_LH_C6R4 0
#define KEY_LH_C5R4 S
#define KEY_LH_C4R4 H
#define KEY_LH_C3R4 N
#define KEY_LH_C2R4 T
#define KEY_LH_C1R4 COMMA
#define KEY_RH_C1R4 DOT
#define KEY_RH_C2R4 A
#define KEY_RH_C3R4 E
#define KEY_RH_C4R4 O
#define KEY_RH_C5R4 I
#define KEY_RH_C6R4 SQT
#define KEY_LH_C6R5 LSHFT
#define KEY_LH_C5R5 F
#define KEY_LH_C4R5 M
#define KEY_LH_C3R5 V
#define KEY_LH_C2R5 C
#define KEY_LH_C1R5 FSLH
#define KEY_LH_T1 ESC
#define KEY_LH_T2 UP
#define KEY_LH_T3 DOWN
#define KEY_RH_T3 LEFT
#define KEY_RH_T2 RIGHT
#define KEY_RH_T1 ENTER
#define KEY_RH_C1R5 G
#define KEY_RH_C2R5 P
#define KEY_RH_C3R5 X
#define KEY_RH_C4R5 K
#define KEY_RH_C5R5 Y
#define KEY_RH_C6R5 RSHFT
#define KEY_LH_C6R6 0
#define KEY_LH_C5R6 HOME
#define KEY_LH_C4R6 PG_UP
#define KEY_LH_C3R6 PG_DN
#define KEY_LH_C2R6 END
#define KEY_LH_T4 BACKSPACE
#define KEY_LH_T5 LSFT
#define KEY_LH_T6 DELETE
#define KEY_RH_T6 TAB
#define KEY_RH_T5 RSFT
#define KEY_RH_T4 SPACE
#define KEY_RH_C2R6 LPAR
#define KEY_RH_C3R6 LBKT
#define KEY_RH_C4R6 RBKT
#define KEY_RH_C5R6 RPAR
#define KEY_RH_C6R6 0
#endif

combos {
    compatible = "zmk,combos";

    //
    // COMBO_FIRING_DECAY defines how much time you have left (milliseconds)
    // after pressing the first key in a ZMK combo to finish the whole chord.
    //
    #ifndef COMBO_FIRING_DECAY
    #define COMBO_FIRING_DECAY 50
    #endif
    #ifdef LAYER_Gaming
    combo_gaming_layer_toggle {
        timeout-ms = <COMBO_FIRING_DECAY>;
        key-positions = <POS_LH_T3 POS_LH_T6>;
        bindings = <&tog LAYER_Gaming>;
        layers = <0 LAYER_Gaming>;
    };
    #endif
    #ifdef _A_TAB
    combo_alt_tab_switcher {
        timeout-ms = <COMBO_FIRING_DECAY>;
        key-positions = <POS_LH_T4 POS_LH_T1>;
        bindings = <&mod_tab_chord _A_TAB LAYER_Cursor>;
        layers = <0 1 2 3 4 5 6 7 8>;
    };
    #endif
};

behaviors {

    //////////////////////////////////////////////////////////////////////////
    //
    // Miryoku layers and home row mods (ported from my QMK endgame)
    // - https://sunaku.github.io/home-row-mods.html#porting-to-zmk
    // - https://github.com/urob/zmk-config#timeless-homerow-mods
    //
    //////////////////////////////////////////////////////////////////////////

    //
    // The *_FINGER_MOD specify which modifiers are used by home row mod keys.
    // Here, we use Miryoku's "GACS" (Win, Alt, Ctrl, Shift) order by default,
    // unless OPERATING_SYSTEM is macOS, in which case Win & Ctrl are swapped.
    //
    #ifndef PINKY_FINGER_MOD
      #if OPERATING_SYSTEM == 'M'
        #define PINKY_FINGER_MOD LCTL
      #else
        #define PINKY_FINGER_MOD LGUI
      #endif
    #endif
    #ifndef RING_FINGER_MOD
    #define RING_FINGER_MOD LALT
    #endif
    #ifndef MIDDY_FINGER_MOD
      #if OPERATING_SYSTEM == 'M'
        #define MIDDY_FINGER_MOD LGUI
      #else
        #define MIDDY_FINGER_MOD LCTL
      #endif
    #endif
    #ifndef INDEX_FINGER_MOD
    #define INDEX_FINGER_MOD LSFT
    #endif
    //
    // The following settings let you configure mods individually, per finger:
    //
    #ifndef LEFT_PINKY_MOD
    #define LEFT_PINKY_MOD  PINKY_FINGER_MOD
    #endif
    #ifndef RIGHT_PINKY_MOD
    #define RIGHT_PINKY_MOD PINKY_FINGER_MOD
    #endif
    #ifndef LEFT_RING_MOD
    #define LEFT_RING_MOD  RING_FINGER_MOD
    #endif
    #ifndef RIGHT_RING_MOD
    #define RIGHT_RING_MOD RING_FINGER_MOD
    #endif
    #ifndef LEFT_MIDDY_MOD
    #define LEFT_MIDDY_MOD  MIDDY_FINGER_MOD
    #endif
    #ifndef RIGHT_MIDDY_MOD
    #define RIGHT_MIDDY_MOD MIDDY_FINGER_MOD
    #endif
    #ifndef LEFT_INDEX_MOD
    #define LEFT_INDEX_MOD  INDEX_FINGER_MOD
    #endif
    #ifndef RIGHT_INDEX_MOD
    #define RIGHT_INDEX_MOD INDEX_FINGER_MOD
    #endif

    //
    // HOMEY_HOLDING_TYPE defines the flavor of ZMK hold-tap behavior to use
    // for the pinky, ring, and middle fingers (which are assigned to Super,
    // Alt, and Ctrl respectively in the Miryoku system) on home row keys.
    //
    #ifndef HOMEY_HOLDING_TYPE
    #define HOMEY_HOLDING_TYPE "tap-preferred"
    #endif

    //
    // HOMEY_HOLDING_TIME defines how long you need to hold (milliseconds)
    // home row mod keys in order to send their modifiers to the computer
    // (i.e. "register" them) for mod-click mouse usage (e.g. Ctrl-Click).
    //
    #ifndef HOMEY_HOLDING_TIME
    #define HOMEY_HOLDING_TIME 240 // TAPPING_TERM + ALLOW_CROSSOVER_AFTER
    #endif

    //
    // HOMEY_STREAK_DECAY defines how long you need to wait (milliseconds)
    // after typing before you can use home row mods again.  It prevents
    // unintended activation of home row mods when you're actively typing.
    //
    #ifndef HOMEY_STREAK_DECAY
    #define HOMEY_STREAK_DECAY 160
    #endif

    //
    // HOMEY_REPEAT_DECAY defines how much time you have left (milliseconds)
    // after tapping a key to hold it again in order to make it auto-repeat.
    //
    #ifndef HOMEY_REPEAT_DECAY
    #define HOMEY_REPEAT_DECAY 300 // "tap then hold" for key auto-repeat
    #endif

    //
    // INDEX_HOLDING_TYPE defines the flavor of ZMK hold-tap behavior to use
    // for index fingers (which Miryoku assigns to Shift) on home row keys.
    //
    // NOTE: The "tap-preferred" flavor of ZMK hold-tap for index finger keys
    // allows faster activation of the Shift modifier (without having to wait
    // for the modified key to be released as the "balanced" flavor requires).
    // Typing streaks and the `hold-trigger-on-release` setting are disabled
    // for the index fingers so as not to hinder their speed and dexterity.
    //
    #ifndef INDEX_HOLDING_TYPE
    #define INDEX_HOLDING_TYPE "tap-preferred"
    #endif

    //
    // INDEX_HOLDING_TIME defines how long you need to hold (milliseconds)
    // index finger keys in order to send their modifiers to the computer
    // (i.e. "register" them) for mod-click mouse usage (e.g. Shift-Click).
    //
    #ifndef INDEX_HOLDING_TIME
    #define INDEX_HOLDING_TIME 180
    #endif

    //
    // INDEX_STREAK_DECAY defines how long you need to wait (milliseconds)
    // after typing before you can use home row mods again.  It prevents
    // unintended activation of home row mods when you're actively typing.
    //
    #ifndef INDEX_STREAK_DECAY
    #define INDEX_STREAK_DECAY 100
    #endif

    //
    // INDEX_REPEAT_DECAY defines how much time you have left (milliseconds)
    // after tapping a key to hold it again in order to make it auto-repeat.
    //
    #ifndef INDEX_REPEAT_DECAY
    #define INDEX_REPEAT_DECAY 300 // "tap then hold" for key auto-repeat
    #endif

    //
    // PLAIN_HOLDING_TYPE defines the flavor of ZMK hold-tap behavior to use
    // for index fingers (which Miryoku assigns to Shift) on home row keys.
    //
    // NOTE: The "tap-preferred" flavor of ZMK hold-tap for index finger keys
    // allows faster activation of the Shift modifier (without having to wait
    // for the modified key to be released as the "balanced" flavor requires).
    // Typing streaks and the `hold-trigger-on-release` setting are disabled
    // for the index fingers so as not to hinder their speed and dexterity.
    //
    #ifndef PLAIN_HOLDING_TYPE
    #define PLAIN_HOLDING_TYPE HOMEY_HOLDING_TYPE
    #endif

    //
    // PLAIN_HOLDING_TIME defines how long you need to hold (milliseconds)
    // index finger keys in order to send their modifiers to the computer
    // (i.e. "register" them) for mod-click mouse usage (e.g. Shift-Click).
    //
    #ifndef PLAIN_HOLDING_TIME
    #define PLAIN_HOLDING_TIME HOMEY_HOLDING_TIME
    #endif

    //
    // PLAIN_STREAK_DECAY defines how long you need to wait (milliseconds)
    // after typing before you can use home row mods again.  It prevents
    // unintended activation of home row mods when you're actively typing.
    //
    #ifndef PLAIN_STREAK_DECAY
    #define PLAIN_STREAK_DECAY HOMEY_STREAK_DECAY
    #endif

    //
    // PLAIN_REPEAT_DECAY defines how much time you have left (milliseconds)
    // after tapping a key to hold it again in order to make it auto-repeat.
    //
    #ifndef PLAIN_REPEAT_DECAY
    #define PLAIN_REPEAT_DECAY 300 // "tap then hold" for key auto-repeat
    #endif

    //
    // THUMB_HOLDING_TYPE defines the flavor of ZMK hold-tap behavior to use
    // for the thumbs (which are assigned to 6 layers in the Miryoku system).
    //
    // NOTE: The "balanced" flavor of ZMK hold-tap provides instant modifier
    // activation for the symbol layer (if the tapped symbol key is released
    // while the thumb layer key is still held down) for quicker programming.
    //
    #ifndef THUMB_HOLDING_TYPE
    #define THUMB_HOLDING_TYPE "balanced"
    #endif

    //
    // THUMB_HOLDING_TIME defines how long you need to hold (milliseconds)
    // a thumb key to activate a layer.  Shorter holds are treated as taps.
    //
    #ifndef THUMB_HOLDING_TIME
    #define THUMB_HOLDING_TIME 200
    #endif

    //
    // THUMB_REPEAT_DECAY defines how much time you have left (milliseconds)
    // after tapping a key to hold it again in order to make it auto-repeat.
    //
    #ifndef THUMB_REPEAT_DECAY
    #define THUMB_REPEAT_DECAY 300 // "tap then hold" for key auto-repeat
    #endif

    //
    // SPACE_HOLDING_TYPE defines the flavor of ZMK hold-tap behavior to use
    // for spacebar (assigned to the right thumb's home position by default).
    //
    // NOTE: The "balanced" flavor of ZMK hold-tap provides instant modifier
    // activation for the symbol layer (if the tapped symbol key is released
    // while the thumb layer key is still held down) for quicker programming.
    //
    #ifndef SPACE_HOLDING_TYPE
    #define SPACE_HOLDING_TYPE THUMB_HOLDING_TYPE
    #endif

    //
    // SPACE_HOLDING_TIME defines how long you need to hold (milliseconds)
    // the space thumb key to activate.  Shorter holds are treated as taps.
    //
    #ifndef SPACE_HOLDING_TIME
    #define SPACE_HOLDING_TIME THUMB_HOLDING_TIME
    #endif

    //
    // SPACE_REPEAT_DECAY defines how much time you have left (milliseconds)
    // after tapping a key to hold it again in order to make it auto-repeat.
    //
    #ifndef SPACE_REPEAT_DECAY
    #define SPACE_REPEAT_DECAY 150
    #endif

    //
    // Glove80 key positions index for positional hold-tap
    // - https://discord.com/channels/877392805654306816/937645688244826154/1066713913351221248
    // - https://media.discordapp.net/attachments/937645688244826154/1066713913133121556/image.png
    //
    // |------------------------|------------------------|
    // | LEFT_HAND_KEYS         |        RIGHT_HAND_KEYS |
    // |                        |                        |
    // |  0  1  2  3  4         |          5  6  7  8  9 |
    // | 10 11 12 13 14 15      |      16 17 18 19 20 21 |
    // | 22 23 24 25 26 27      |      28 29 30 31 32 33 |
    // | 34 35 36 37 38 39      |      40 41 42 43 44 45 |
    // | 46 47 48 49 50 51      |      58 59 60 61 62 63 |
    // | 64 65 66 67 68         |         75 76 77 78 79 |
    // |                69 52   |   57 74                |
    // |                 70 53  |  56 73                 |
    // |                  71 54 | 55 72                  |
    // |------------------------|------------------------|
    //
    #define LEFT_HAND_KEYS      \
          0  1  2  3  4         \
         10 11 12 13 14 15      \
         22 23 24 25 26 27      \
         34 35 36 37 38 39      \
         46 47 48 49 50 51      \
         64 65 66 67 68
    #define RIGHT_HAND_KEYS     \
                                           5  6  7  8  9 \
                                       16 17 18 19 20 21 \
                                       28 29 30 31 32 33 \
                                       40 41 42 43 44 45 \
                                       58 59 60 61 62 63 \
                                          75 76 77 78 79
    #define THUMB_KEYS          \
                        69 52       57 74                \
                         70 53     56 73                 \
                          71 54   55 72

    #define LEFT_PINKY_KEY  KEY_LH_C5R4
    #define LEFT_RING_KEY  KEY_LH_C4R4
    #define LEFT_MIDDY_KEY  KEY_LH_C3R4
    #define LEFT_INDEX_KEY  KEY_LH_C2R4
    #define LEFT_PLAIN_KEY  KEY_LH_C1R4

    #define RIGHT_PINKY_KEY KEY_RH_C5R4
    #define RIGHT_RING_KEY KEY_RH_C4R4
    #define RIGHT_MIDDY_KEY KEY_RH_C3R4
    #define RIGHT_INDEX_KEY KEY_RH_C2R4
    #define RIGHT_PLAIN_KEY KEY_RH_C1R4
    #if defined(LAYER_Engram) && LAYER_Engram == 0
    #define LeftPlainKey  engram_COMMA
    #define RightPlainKey engram_DOT
    #else
    #define LeftPlainKey  kp LEFT_PLAIN_KEY
    #define RightPlainKey kp RIGHT_PLAIN_KEY
    #endif

    //
    // Studio-editable home-row modifiers
    //
    // Bilateral enforcement is selected at compile time without duplicating
    // the per-finger behavior nodes or their Studio metadata.
    //
#define HOME_ROW_MOD(name) &name

#ifndef HRM_LINGER_TIME
#define HRM_LINGER_TIME 100
#endif

#ifndef LEFT_PINKY_HOLDING_TYPE
#define LEFT_PINKY_HOLDING_TYPE HOMEY_HOLDING_TYPE
#endif
#ifndef LEFT_PINKY_HOLDING_TIME
#define LEFT_PINKY_HOLDING_TIME HOMEY_HOLDING_TIME
#endif
#ifndef LEFT_PINKY_STREAK_DECAY
#define LEFT_PINKY_STREAK_DECAY HOMEY_STREAK_DECAY
#endif
#ifndef LEFT_PINKY_REPEAT_DECAY
#define LEFT_PINKY_REPEAT_DECAY HOMEY_REPEAT_DECAY
#endif
    left_pinky: homey_left_pinky {
        compatible = "zmk,behavior-hold-tap";
        display-name = "Left Pinky HRM";
        flavor = LEFT_PINKY_HOLDING_TYPE;
        hold-trigger-key-positions = <RIGHT_HAND_KEYS THUMB_KEYS>;
        hold-trigger-on-release;
#ifdef USE_BILATERAL_HOLD_TAPS
        enforce-bilateral;
#endif // USE_BILATERAL_HOLD_TAPS
        linger-ms = <HRM_LINGER_TIME>;
        tapping-term-ms = <LEFT_PINKY_HOLDING_TIME>;
        quick-tap-ms = <LEFT_PINKY_REPEAT_DECAY>;
        require-prior-idle-ms = <LEFT_PINKY_STREAK_DECAY>;
        #binding-cells = <2>;
        bindings = <&kp>, <&kp>;
    };
#ifndef RIGHT_PINKY_HOLDING_TYPE
#define RIGHT_PINKY_HOLDING_TYPE HOMEY_HOLDING_TYPE
#endif
#ifndef RIGHT_PINKY_HOLDING_TIME
#define RIGHT_PINKY_HOLDING_TIME HOMEY_HOLDING_TIME
#endif
#ifndef RIGHT_PINKY_STREAK_DECAY
#define RIGHT_PINKY_STREAK_DECAY HOMEY_STREAK_DECAY
#endif
#ifndef RIGHT_PINKY_REPEAT_DECAY
#define RIGHT_PINKY_REPEAT_DECAY HOMEY_REPEAT_DECAY
#endif
    right_pinky: homey_right_pinky {
        compatible = "zmk,behavior-hold-tap";
        display-name = "Right Pinky HRM";
        flavor = RIGHT_PINKY_HOLDING_TYPE;
        hold-trigger-key-positions = <LEFT_HAND_KEYS THUMB_KEYS>;
        hold-trigger-on-release;
#ifdef USE_BILATERAL_HOLD_TAPS
        enforce-bilateral;
#endif // USE_BILATERAL_HOLD_TAPS
        linger-ms = <HRM_LINGER_TIME>;
        tapping-term-ms = <RIGHT_PINKY_HOLDING_TIME>;
        quick-tap-ms = <RIGHT_PINKY_REPEAT_DECAY>;
        require-prior-idle-ms = <RIGHT_PINKY_STREAK_DECAY>;
        #binding-cells = <2>;
        bindings = <&kp>, <&kp>;
    };
#ifndef LEFT_RING_HOLDING_TYPE
#define LEFT_RING_HOLDING_TYPE HOMEY_HOLDING_TYPE
#endif
#ifndef LEFT_RING_HOLDING_TIME
#define LEFT_RING_HOLDING_TIME HOMEY_HOLDING_TIME
#endif
#ifndef LEFT_RING_STREAK_DECAY
#define LEFT_RING_STREAK_DECAY HOMEY_STREAK_DECAY
#endif
#ifndef LEFT_RING_REPEAT_DECAY
#define LEFT_RING_REPEAT_DECAY HOMEY_REPEAT_DECAY
#endif
    left_ring: homey_left_ring {
        compatible = "zmk,behavior-hold-tap";
        display-name = "Left Ring HRM";
        flavor = LEFT_RING_HOLDING_TYPE;
        hold-trigger-key-positions = <RIGHT_HAND_KEYS THUMB_KEYS>;
        hold-trigger-on-release;
#ifdef USE_BILATERAL_HOLD_TAPS
        enforce-bilateral;
#endif // USE_BILATERAL_HOLD_TAPS
        linger-ms = <HRM_LINGER_TIME>;
        tapping-term-ms = <LEFT_RING_HOLDING_TIME>;
        quick-tap-ms = <LEFT_RING_REPEAT_DECAY>;
        require-prior-idle-ms = <LEFT_RING_STREAK_DECAY>;
        #binding-cells = <2>;
        bindings = <&kp>, <&kp>;
    };
#ifndef RIGHT_RING_HOLDING_TYPE
#define RIGHT_RING_HOLDING_TYPE HOMEY_HOLDING_TYPE
#endif
#ifndef RIGHT_RING_HOLDING_TIME
#define RIGHT_RING_HOLDING_TIME HOMEY_HOLDING_TIME
#endif
#ifndef RIGHT_RING_STREAK_DECAY
#define RIGHT_RING_STREAK_DECAY HOMEY_STREAK_DECAY
#endif
#ifndef RIGHT_RING_REPEAT_DECAY
#define RIGHT_RING_REPEAT_DECAY HOMEY_REPEAT_DECAY
#endif
    right_ring: homey_right_ring {
        compatible = "zmk,behavior-hold-tap";
        display-name = "Right Ring HRM";
        flavor = RIGHT_RING_HOLDING_TYPE;
        hold-trigger-key-positions = <LEFT_HAND_KEYS THUMB_KEYS>;
        hold-trigger-on-release;
#ifdef USE_BILATERAL_HOLD_TAPS
        enforce-bilateral;
#endif // USE_BILATERAL_HOLD_TAPS
        linger-ms = <HRM_LINGER_TIME>;
        tapping-term-ms = <RIGHT_RING_HOLDING_TIME>;
        quick-tap-ms = <RIGHT_RING_REPEAT_DECAY>;
        require-prior-idle-ms = <RIGHT_RING_STREAK_DECAY>;
        #binding-cells = <2>;
        bindings = <&kp>, <&kp>;
    };
#ifndef LEFT_MIDDY_HOLDING_TYPE
#define LEFT_MIDDY_HOLDING_TYPE HOMEY_HOLDING_TYPE
#endif
#ifndef LEFT_MIDDY_HOLDING_TIME
#define LEFT_MIDDY_HOLDING_TIME HOMEY_HOLDING_TIME
#endif
#ifndef LEFT_MIDDY_STREAK_DECAY
#define LEFT_MIDDY_STREAK_DECAY HOMEY_STREAK_DECAY
#endif
#ifndef LEFT_MIDDY_REPEAT_DECAY
#define LEFT_MIDDY_REPEAT_DECAY HOMEY_REPEAT_DECAY
#endif
    left_middy: homey_left_middy {
        compatible = "zmk,behavior-hold-tap";
        display-name = "Left Middy HRM";
        flavor = LEFT_MIDDY_HOLDING_TYPE;
        hold-trigger-key-positions = <RIGHT_HAND_KEYS THUMB_KEYS>;
        hold-trigger-on-release;
#ifdef USE_BILATERAL_HOLD_TAPS
        enforce-bilateral;
#endif // USE_BILATERAL_HOLD_TAPS
        linger-ms = <HRM_LINGER_TIME>;
        tapping-term-ms = <LEFT_MIDDY_HOLDING_TIME>;
        quick-tap-ms = <LEFT_MIDDY_REPEAT_DECAY>;
        require-prior-idle-ms = <LEFT_MIDDY_STREAK_DECAY>;
        #binding-cells = <2>;
        bindings = <&kp>, <&kp>;
    };
#ifndef RIGHT_MIDDY_HOLDING_TYPE
#define RIGHT_MIDDY_HOLDING_TYPE HOMEY_HOLDING_TYPE
#endif
#ifndef RIGHT_MIDDY_HOLDING_TIME
#define RIGHT_MIDDY_HOLDING_TIME HOMEY_HOLDING_TIME
#endif
#ifndef RIGHT_MIDDY_STREAK_DECAY
#define RIGHT_MIDDY_STREAK_DECAY HOMEY_STREAK_DECAY
#endif
#ifndef RIGHT_MIDDY_REPEAT_DECAY
#define RIGHT_MIDDY_REPEAT_DECAY HOMEY_REPEAT_DECAY
#endif
    right_middy: homey_right_middy {
        compatible = "zmk,behavior-hold-tap";
        display-name = "Right Middy HRM";
        flavor = RIGHT_MIDDY_HOLDING_TYPE;
        hold-trigger-key-positions = <LEFT_HAND_KEYS THUMB_KEYS>;
        hold-trigger-on-release;
#ifdef USE_BILATERAL_HOLD_TAPS
        enforce-bilateral;
#endif // USE_BILATERAL_HOLD_TAPS
        linger-ms = <HRM_LINGER_TIME>;
        tapping-term-ms = <RIGHT_MIDDY_HOLDING_TIME>;
        quick-tap-ms = <RIGHT_MIDDY_REPEAT_DECAY>;
        require-prior-idle-ms = <RIGHT_MIDDY_STREAK_DECAY>;
        #binding-cells = <2>;
        bindings = <&kp>, <&kp>;
    };
#ifndef LEFT_INDEX_HOLDING_TYPE
#define LEFT_INDEX_HOLDING_TYPE INDEX_HOLDING_TYPE
#endif
#ifndef LEFT_INDEX_HOLDING_TIME
#define LEFT_INDEX_HOLDING_TIME INDEX_HOLDING_TIME
#endif
#ifndef LEFT_INDEX_STREAK_DECAY
#define LEFT_INDEX_STREAK_DECAY INDEX_STREAK_DECAY
#endif
#ifndef LEFT_INDEX_REPEAT_DECAY
#define LEFT_INDEX_REPEAT_DECAY INDEX_REPEAT_DECAY
#endif
    left_index: homey_left_index {
        compatible = "zmk,behavior-hold-tap";
        display-name = "Left Index HRM";
        flavor = LEFT_INDEX_HOLDING_TYPE;
        hold-trigger-key-positions = <RIGHT_HAND_KEYS THUMB_KEYS>;
        hold-trigger-on-release;
#ifdef USE_BILATERAL_HOLD_TAPS
        enforce-bilateral;
#endif // USE_BILATERAL_HOLD_TAPS
        linger-ms = <HRM_LINGER_TIME>;
        tapping-term-ms = <LEFT_INDEX_HOLDING_TIME>;
        quick-tap-ms = <LEFT_INDEX_REPEAT_DECAY>;
        require-prior-idle-ms = <LEFT_INDEX_STREAK_DECAY>;
        #binding-cells = <2>;
        bindings = <&kp>, <&kp>;
    };
#ifndef RIGHT_INDEX_HOLDING_TYPE
#define RIGHT_INDEX_HOLDING_TYPE INDEX_HOLDING_TYPE
#endif
#ifndef RIGHT_INDEX_HOLDING_TIME
#define RIGHT_INDEX_HOLDING_TIME INDEX_HOLDING_TIME
#endif
#ifndef RIGHT_INDEX_STREAK_DECAY
#define RIGHT_INDEX_STREAK_DECAY INDEX_STREAK_DECAY
#endif
#ifndef RIGHT_INDEX_REPEAT_DECAY
#define RIGHT_INDEX_REPEAT_DECAY INDEX_REPEAT_DECAY
#endif
    right_index: homey_right_index {
        compatible = "zmk,behavior-hold-tap";
        display-name = "Right Index HRM";
        flavor = RIGHT_INDEX_HOLDING_TYPE;
        hold-trigger-key-positions = <LEFT_HAND_KEYS THUMB_KEYS>;
        hold-trigger-on-release;
#ifdef USE_BILATERAL_HOLD_TAPS
        enforce-bilateral;
#endif // USE_BILATERAL_HOLD_TAPS
        linger-ms = <HRM_LINGER_TIME>;
        tapping-term-ms = <RIGHT_INDEX_HOLDING_TIME>;
        quick-tap-ms = <RIGHT_INDEX_REPEAT_DECAY>;
        require-prior-idle-ms = <RIGHT_INDEX_STREAK_DECAY>;
        #binding-cells = <2>;
        bindings = <&kp>, <&kp>;
    };

    //
    // Key repetition access keys on the index fingers
    //
    plain: plain_typing_layer {
        compatible = "zmk,behavior-hold-tap";
        flavor = PLAIN_HOLDING_TYPE;
        tapping-term-ms = <PLAIN_HOLDING_TIME>;
        quick-tap-ms = <PLAIN_REPEAT_DECAY>; // enable repeat
        require-prior-idle-ms = <PLAIN_STREAK_DECAY>;
        #binding-cells = <2>;
        bindings = <&mo>, <&kp>;
        retro-tap; // tap on standalone hold
    };
    plain_engram_COMMA: plain_typing_layer_engram_COMMA {
        compatible = "zmk,behavior-hold-tap";
        flavor = PLAIN_HOLDING_TYPE;
        tapping-term-ms = <PLAIN_HOLDING_TIME>;
        quick-tap-ms = <PLAIN_REPEAT_DECAY>; // enable repeat
        require-prior-idle-ms = <PLAIN_STREAK_DECAY>;
        #binding-cells = <2>;
        bindings = <&mo>, <&engram_COMMA>;
        retro-tap; // tap on standalone hold
    };
    plain_engram_DOT: plain_typing_layer_engram_DOT {
        compatible = "zmk,behavior-hold-tap";
        flavor = PLAIN_HOLDING_TYPE;
        tapping-term-ms = <PLAIN_HOLDING_TIME>;
        quick-tap-ms = <PLAIN_REPEAT_DECAY>; // enable repeat
        require-prior-idle-ms = <PLAIN_STREAK_DECAY>;
        #binding-cells = <2>;
        bindings = <&mo>, <&engram_DOT>;
        retro-tap; // tap on standalone hold
    };

    //
    // Thumb cluster hold-tap keys for Miryoku layers
    //
    thumb: thumb_layer_access {
        compatible = "zmk,behavior-hold-tap";
        flavor = THUMB_HOLDING_TYPE;
        tapping-term-ms = <THUMB_HOLDING_TIME>;
        quick-tap-ms = <THUMB_REPEAT_DECAY>; // enable repeat
        #binding-cells = <2>;
        bindings = <&mo>, <&kp>;
    };
    thumb_tog: thumb_layer_access_tog {
        compatible = "zmk,behavior-hold-tap";
        flavor = THUMB_HOLDING_TYPE;
        tapping-term-ms = <THUMB_HOLDING_TIME>;
        quick-tap-ms = <THUMB_REPEAT_DECAY>; // enable repeat
        #binding-cells = <2>;
        bindings = <&tog>, <&sticky_key_oneshot>;
    };
    thumb_parang_left: thumb_layer_access_parang_left {
        compatible = "zmk,behavior-hold-tap";
        flavor = THUMB_HOLDING_TYPE;
        tapping-term-ms = <THUMB_HOLDING_TIME>;
        quick-tap-ms = <THUMB_REPEAT_DECAY>; // enable repeat
        #binding-cells = <2>;
        bindings = <&mo>, <&parang_left>;
    };
    thumb_lower_shift: lower_layer_or_sticky_shift {
        compatible = "zmk,behavior-hold-tap";
        flavor = "tap-preferred";
        tapping-term-ms = <THUMB_HOLDING_TIME>;
        #binding-cells = <2>;
        bindings = <&mo>, <&sticky_key_oneshot>;
    };
    space: thumb_layer_access_spacebar {
        compatible = "zmk,behavior-hold-tap";
        flavor = SPACE_HOLDING_TYPE;
        tapping-term-ms = <SPACE_HOLDING_TIME>;
        quick-tap-ms = <SPACE_REPEAT_DECAY>; // enable repeat
        #binding-cells = <2>;
        bindings = <&mo>, <&kp>;
    };

    //
    // Shift + LEFT_PARENTHESIS = LESS_THAN
    //
    parang_left: left_parenthesis_and_less_than {
        compatible = "zmk,behavior-mod-morph";
        #binding-cells = <0>;
        bindings = <&kp LPAR>, <&kp LT>;
        mods = <(MOD_LSFT|MOD_RSFT)>;
    };

    //
    // Shift + RIGHT_PARENTHESIS = GREATER_THAN
    //
    parang_right: right_parenthesis_and_greater_than {
        compatible = "zmk,behavior-mod-morph";
        #binding-cells = <0>;
        bindings = <&kp RPAR>, <&kp GT>;
        mods = <(MOD_LSFT|MOD_RSFT)>;
    };

    //
    // Custom shifted pairs for the Engram layout
    // - https://engram.dev/
    // - https://sunaku.github.io/engram-keyboard-layout.html
    //
    engram_N1: engram_shift_N1_PIPE {
        compatible = "zmk,behavior-mod-morph";
        #binding-cells = <0>;
        bindings = <&kp N1>, <&kp PIPE>;
        mods = <(MOD_LSFT|MOD_RSFT)>;
    };
    engram_N2: engram_shift_N2_EQUAL {
        compatible = "zmk,behavior-mod-morph";
        #binding-cells = <0>;
        bindings = <&kp N2>, <&kp EQUAL>;
        mods = <(MOD_LSFT|MOD_RSFT)>;
    };
    engram_N3: engram_shift_N3_TILDE {
        compatible = "zmk,behavior-mod-morph";
        #binding-cells = <0>;
        bindings = <&kp N3>, <&kp TILDE>;
        mods = <(MOD_LSFT|MOD_RSFT)>;
    };
    engram_N4: engram_shift_N4_PLUS {
        compatible = "zmk,behavior-mod-morph";
        #binding-cells = <0>;
        bindings = <&kp N4>, <&kp PLUS>;
        mods = <(MOD_LSFT|MOD_RSFT)>;
    };
    engram_N5: engram_shift_N5_LT {
        compatible = "zmk,behavior-mod-morph";
        #binding-cells = <0>;
        bindings = <&kp N5>, <&kp LT>;
        mods = <(MOD_LSFT|MOD_RSFT)>;
    };
    engram_N6: engram_shift_N6_GT {
        compatible = "zmk,behavior-mod-morph";
        #binding-cells = <0>;
        bindings = <&kp N6>, <&kp GT>;
        mods = <(MOD_LSFT|MOD_RSFT)>;
    };
    engram_N7: engram_shift_N7_CARET {
        compatible = "zmk,behavior-mod-morph";
        #binding-cells = <0>;
        bindings = <&kp N7>, <&kp CARET>;
        mods = <(MOD_LSFT|MOD_RSFT)>;
    };
    engram_N8: engram_shift_N8_AMPS {
        compatible = "zmk,behavior-mod-morph";
        #binding-cells = <0>;
        bindings = <&kp N8>, <&kp AMPS>;
        mods = <(MOD_LSFT|MOD_RSFT)>;
    };
    engram_N9: engram_shift_N9_PRCNT {
        compatible = "zmk,behavior-mod-morph";
        #binding-cells = <0>;
        bindings = <&kp N9>, <&kp PRCNT>;
        mods = <(MOD_LSFT|MOD_RSFT)>;
    };
    engram_N0: engram_shift_N0_STAR {
        compatible = "zmk,behavior-mod-morph";
        #binding-cells = <0>;
        bindings = <&kp N0>, <&kp STAR>;
        mods = <(MOD_LSFT|MOD_RSFT)>;
    };
    engram_SQT: engram_shift_SQT_LPAR {
        compatible = "zmk,behavior-mod-morph";
        #binding-cells = <0>;
        bindings = <&kp SQT>, <&kp LPAR>;
        mods = <(MOD_LSFT|MOD_RSFT)>;
    };
    engram_DQT: engram_shift_DQT_RPAR {
        compatible = "zmk,behavior-mod-morph";
        #binding-cells = <0>;
        bindings = <&kp DQT>, <&kp RPAR>;
        mods = <(MOD_LSFT|MOD_RSFT)>;
    };
    engram_COMMA: engram_shift_COMMA_SEMI {
        compatible = "zmk,behavior-mod-morph";
        #binding-cells = <0>;
        bindings = <&kp COMMA>, <&kp SEMI>;
        mods = <(MOD_LSFT|MOD_RSFT)>;
    };
    engram_DOT: engram_shift_DOT_COLON {
        compatible = "zmk,behavior-mod-morph";
        #binding-cells = <0>;
        bindings = <&kp DOT>, <&kp COLON>;
        mods = <(MOD_LSFT|MOD_RSFT)>;
    };
    engram_QMARK: engram_shift_QMARK_EXCL {
        compatible = "zmk,behavior-mod-morph";
        #binding-cells = <0>;
        bindings = <&kp QMARK>, <&kp EXCL>;
        mods = <(MOD_LSFT|MOD_RSFT)>;
    };
    engram_HASH: engram_shift_HASH_DLLR {
        compatible = "zmk,behavior-mod-morph";
        #binding-cells = <0>;
        bindings = <&kp HASH>, <&kp DLLR>;
        mods = <(MOD_LSFT|MOD_RSFT)>;
    };
    engram_AT: engram_shift_AT_GRAVE {
        compatible = "zmk,behavior-mod-morph";
        #binding-cells = <0>;
        bindings = <&kp AT>, <&kp GRAVE>;
        mods = <(MOD_LSFT|MOD_RSFT)>;
    };
    engram_FSLH: engram_shift_FSLH_BSLH {
        compatible = "zmk,behavior-mod-morph";
        #binding-cells = <0>;
        bindings = <&kp FSLH>, <&kp BSLH>;
        mods = <(MOD_LSFT|MOD_RSFT)>;
    };

    //////////////////////////////////////////////////////////////////////////
    //
    // &sk (sticky key) variant that is truly one-shot
    //
    //////////////////////////////////////////////////////////////////////////

    //
    // STICKY_1SHOT_DECAY defines how much time you have left (milliseconds)
    // after tapping a sticky key before it expires (won't apply to next tap).
    //
    #ifndef STICKY_1SHOT_DECAY
    #define STICKY_1SHOT_DECAY 500
    #endif

    sticky_key_oneshot: sticky_key_oneshot_macro {
        compatible = "zmk,behavior-macro-one-param";
        wait-ms = <0>;
        tap-ms = <0>;
        #binding-cells = <1>;
        bindings
            = <&macro_param_1to1>
            , <&macro_tap &sticky_key_quickrel MACRO_PLACEHOLDER>
            ;
    };
    sticky_key_quickrel: sticky_key_quick_release {
        compatible = "zmk,behavior-sticky-key";
        #binding-cells = <1>;
        bindings = <&kp>;
        release-after-ms = <STICKY_1SHOT_DECAY>;
        quick-release;
        ignore-modifiers;
    };

    //////////////////////////////////////////////////////////////////////////
    //
    // ZMK global overrides
    //
    //////////////////////////////////////////////////////////////////////////

    //
    // CapsWord - ported from Pascal Getreuer's extension for QMK
    // - https://zmk.dev/docs/behaviors/caps-word
    // - https://getreuer.info/posts/keyboards/caps-word/index.html
    //
    caps_word {
        continue-list = <
            UNDERSCORE MINUS
            BACKSPACE DELETE
            N1 N2 N3 N4 N5 N6 N7 N8 N9 N0
            LSFT RSFT
        >;
    };

    // Sticky layer tap
    slt: sticky_layer_tap {
        compatible = "zmk,behavior-hold-tap";
        #binding-cells = <2>;
        flavor = "hold-preferred";
        tapping-term-ms = <THUMB_HOLDING_TIME>;
        bindings = <&sl>, <&kp>;
    };

    // Toggle layer tap
    tto: tap_to {
        compatible = "zmk,behavior-hold-tap";
        #binding-cells = <2>;
        flavor = "tap-preferred";
        tapping-term-ms = <THUMB_HOLDING_TIME>;
        bindings = <&tog>, <&kp>;
    };

    // Sticky hold tap
    shlt: sticky_hold_tap {
        compatible = "zmk,behavior-hold-tap";
        #binding-cells = <2>;
        quick-tap-ms = <THUMB_REPEAT_DECAY>;
        flavor = "hold-preferred";
        tapping-term-ms = <THUMB_HOLDING_TIME>;
        bindings = <&skq>, <&kp>;
    };

    // Sticky key with quick release
    skq: sticky_key_quick {
        compatible = "zmk,behavior-sticky-key";
        #binding-cells = <1>;
        bindings = <&kp>;
        release-after-ms = <1000>;
        quick-release;
        ignore-modifiers;
    };

    q_btn: q_button {
        compatible = "zmk,behavior-antecedent-morph";
        label = "ADAPTIVE_Q";
        #binding-cells = <0>;
        defaults = <&kp Q>;
        bindings = <&kp U>;
        antecedents = <Q>;
        max-delay-ms = <QU_RESET_TIME>;
    };
};

macros {
    //
    // Linux Magic System Request Key - hold this down and type REISUB
    // - https://www.kernel.org/doc/html/latest/admin-guide/sysrq.html
    // - https://github.com/manna-harbour/miryoku/discussions/259
    //
    ZMK_MACRO(linux_magic_sysrq,
        wait-ms = <0>;
        tap-ms = <0>;
        bindings
            = <&macro_press &mo 0 &kp RALT>
            , <&macro_tap &kp PRINTSCREEN>
            , <&macro_pause_for_release>
            , <&macro_release &mo 0 &kp RALT>
            ;
    )

    //
    // Mod+Tab application switcher - hold this down to keep menu open
    //
    mod_tab: mod_tab_switcher {
        compatible = "zmk,behavior-macro-one-param";
        wait-ms = <0>;
        tap-ms = <0>;
        #binding-cells = <1>;
        bindings
            = <&macro_param_1to1>
            , <&macro_press &kp MACRO_PLACEHOLDER>
            , <&macro_tap &kp TAB>
            , <&macro_pause_for_release>
            , <&macro_param_1to1>
            , <&macro_release &kp MACRO_PLACEHOLDER>
            ;
    };
    mod_tab_chord: mod_tab_switcher_chord {
        compatible = "zmk,behavior-macro-two-param";
        wait-ms = <0>;
        tap-ms = <0>;
        #binding-cells = <2>;
        bindings
            = <&macro_param_2to1>
            , <&macro_press &mo MACRO_PLACEHOLDER>
            , <&macro_param_1to1>
            , <&macro_press &mod_tab MACRO_PLACEHOLDER>
            , <&macro_pause_for_release>
            , <&macro_param_1to1>
            , <&macro_release &mod_tab MACRO_PLACEHOLDER>
            , <&macro_param_2to1>
            , <&macro_release &mo MACRO_PLACEHOLDER>
            ;
    };

    //////////////////////////////////////////////////////////////////////////
    //
    // Approximation of Pascal Getreuer's Select Word macro from QMK
    // - https://getreuer.info/posts/keyboards/select-word/index.html
    //
    //////////////////////////////////////////////////////////////////////////

    //
    // SELECT_WORD_DELAY defines how long the macro waits (milliseconds)
    // after moving the cursor before it selects a word.  A larger delay
    // may allow the macro to move to the next word upon each invocation.
    //
    #ifndef SELECT_WORD_DELAY
    #define SELECT_WORD_DELAY 1
    #endif

    ZMK_MACRO(select_none,
        wait-ms = <SELECT_WORD_DELAY>;
        tap-ms = <SELECT_WORD_DELAY>;
        bindings = <&kp DOWN &kp UP &kp RIGHT &kp LEFT>;
    )

    //
    // select a word (jumps to next word upon each successive invocation)
    //
    select_word: select_word {
        compatible = "zmk,behavior-mod-morph";
        #binding-cells = <0>;
        bindings = <&select_word_right>, <&select_word_left>;
        mods = <(MOD_LSFT|MOD_RSFT)>;
    };
    ZMK_MACRO(select_word_right,
        wait-ms = <SELECT_WORD_DELAY>;
        tap-ms = <SELECT_WORD_DELAY>;
        bindings = <&macro_tap &kp _W(RIGHT) &kp _W(LEFT)>, <&macro_press &kp _W(LS(RIGHT))>, <&macro_pause_for_release>, <&macro_release &kp _W(LS(RIGHT))>;
    )
    ZMK_MACRO(select_word_left,
        wait-ms = <SELECT_WORD_DELAY>;
        tap-ms = <SELECT_WORD_DELAY>;
        bindings = <&macro_tap &kp _W(LEFT) &kp _W(RIGHT)>, <&macro_press &kp _W(LS(LEFT))>, <&macro_pause_for_release>, <&macro_release &kp _W(LS(LEFT))>;
    )

    //
    // extend current selection by one word
    //
    extend_word: extend_word {
        compatible = "zmk,behavior-mod-morph";
        #binding-cells = <0>;
        bindings = <&extend_word_right>, <&extend_word_left>;
        mods = <(MOD_LSFT|MOD_RSFT)>;
    };
    ZMK_MACRO(extend_word_right,
        wait-ms = <SELECT_WORD_DELAY>;
        tap-ms = <SELECT_WORD_DELAY>;
        bindings = <&macro_press &kp _W(LS(RIGHT))>, <&macro_pause_for_release>, <&macro_release &kp _W(LS(RIGHT))>;
    )
    ZMK_MACRO(extend_word_left,
        wait-ms = <SELECT_WORD_DELAY>;
        tap-ms = <SELECT_WORD_DELAY>;
        bindings = <&macro_press &kp _W(LS(LEFT))>, <&macro_pause_for_release>, <&macro_release &kp _W(LS(LEFT))>;
    )

    //
    // select current line
    //
    select_line: select_line {
        compatible = "zmk,behavior-mod-morph";
        #binding-cells = <0>;
        bindings = <&select_line_right>, <&select_line_left>;
        mods = <(MOD_LSFT|MOD_RSFT)>;
    };
    ZMK_MACRO(select_line_right,
        wait-ms = <SELECT_WORD_DELAY>;
        tap-ms = <SELECT_WORD_DELAY>;
        bindings = <&macro_tap &kp _HOME>, <&macro_press &kp LS(DOWN)>, <&macro_pause_for_release>, <&macro_release &kp LS(DOWN)>, <&macro_tap &kp LS(UP) &kp LS(_END)>;
    )
    ZMK_MACRO(select_line_left,
        wait-ms = <SELECT_WORD_DELAY>;
        tap-ms = <SELECT_WORD_DELAY>;
        bindings = <&macro_tap &kp _END>, <&macro_press &kp LS(UP)>, <&macro_pause_for_release>, <&macro_release &kp LS(UP)>, <&macro_tap &kp LS(DOWN) &kp LS(_HOME)>;
    )

    //
    // extend current selection by one line
    //
    extend_line: extend_line {
        compatible = "zmk,behavior-mod-morph";
        #binding-cells = <0>;
        bindings = <&extend_line_right>, <&extend_line_left>;
        mods = <(MOD_LSFT|MOD_RSFT)>;
    };
    ZMK_MACRO(extend_line_right,
        wait-ms = <SELECT_WORD_DELAY>;
        tap-ms = <SELECT_WORD_DELAY>;
        bindings = <&macro_press &kp LS(DOWN)>, <&macro_pause_for_release>, <&macro_release &kp LS(DOWN)>, <&macro_tap &kp LS(_END)>;
    )
    ZMK_MACRO(extend_line_left,
        wait-ms = <SELECT_WORD_DELAY>;
        tap-ms = <SELECT_WORD_DELAY>;
        bindings = <&macro_press &kp LS(UP)>, <&macro_pause_for_release>, <&macro_release &kp LS(UP)>, <&macro_tap &kp LS(_HOME)>;
    )

};

//////////////////////////////////////////////////////////////////////////
//
// Mouse keys (control mouse via keyboard) -- requires PR23 beta firmware:
// select "community.pr23.mouse-keys" from the drop-down menu located at
// Glove80 Layout Editor > Settings > Advanced Settings > Firmware Version
//
// - https://github.com/moergo-sc/zmk/pull/23
// - https://gist.github.com/krissen/dd27082e7ab0575619c7a31f4d2ec7ae
// - https://github.com/zmkfirmware/zmk/compare/main...urob:zmk:mouse-3.2
//
//////////////////////////////////////////////////////////////////////////

//
// MOUSE_MOTION_DELAY defines how long to wait (milliseconds) before starting
// to move the mouse pointer.
//
#ifndef MOUSE_MOTION_DELAY
#define MOUSE_MOTION_DELAY 0
#endif

//
// MOUSE_MOTION_ACCELERATION_EXPONENT sets how the mouse pointer accelerates:
//
// acceleration exponent 0: uniform speed
// acceleration exponent 1: uniform acceleration
// acceleration exponent 2: uniform jerk
//
#ifndef MOUSE_MOTION_ACCELERATION_EXPONENT
#define MOUSE_MOTION_ACCELERATION_EXPONENT 1
#endif

//
// MOUSE_MOTION_TIME_TO_MAXIMUM_SPEED defines how long to wait (milliseconds)
// before the mouse pointer speed is suddenly boosted to the maximum value.
//
#ifndef MOUSE_MOTION_TIME_TO_MAXIMUM_SPEED
#define MOUSE_MOTION_TIME_TO_MAXIMUM_SPEED 900
#endif

//
// MOUSE_MOTION_MAXIMUM_SPEED defines how quickly the mouse pointer can move.
//
#ifndef MOUSE_MOTION_MAXIMUM_SPEED
#define MOUSE_MOTION_MAXIMUM_SPEED 1200
#endif

//
// MOUSE_SCROLL_DELAY defines how long to wait (milliseconds) before starting
// to move the mouse pointer.
//
#ifndef MOUSE_SCROLL_DELAY
#define MOUSE_SCROLL_DELAY 0
#endif

//
// MOUSE_SCROLL_ACCELERATION_EXPONENT sets how the mouse pointer accelerates:
//
// acceleration exponent 0: uniform speed
// acceleration exponent 1: uniform acceleration
// acceleration exponent 2: uniform jerk
//
#ifndef MOUSE_SCROLL_ACCELERATION_EXPONENT
#define MOUSE_SCROLL_ACCELERATION_EXPONENT 1
#endif

//
// MOUSE_SCROLL_TIME_TO_MAXIMUM_SPEED defines how long to wait (milliseconds)
// before the mouse pointer speed is suddenly boosted to the maximum value.
//
#ifndef MOUSE_SCROLL_TIME_TO_MAXIMUM_SPEED
#define MOUSE_SCROLL_TIME_TO_MAXIMUM_SPEED 900
#endif

//
// MOUSE_SCROLL_MAXIMUM_SPEED defines how quickly the mouse wheel can scroll.
//
#ifndef MOUSE_SCROLL_MAXIMUM_SPEED
#define MOUSE_SCROLL_MAXIMUM_SPEED 45
#endif
};
// ==== MOUSE-KEY <section begins> ====
#define ZMK_POINTING_DEFAULT_MOVE_VAL MOUSE_MOTION_MAXIMUM_SPEED
#define ZMK_POINTING_DEFAULT_SCRL_VAL MOUSE_SCROLL_MAXIMUM_SPEED
#include <dt-bindings/zmk/mouse.h>
&mmv {
    delay-ms = <MOUSE_MOTION_DELAY>;
    acceleration-exponent = <MOUSE_MOTION_ACCELERATION_EXPONENT>;
    time-to-max-speed-ms = <MOUSE_MOTION_TIME_TO_MAXIMUM_SPEED>;
};
&msc {
    delay-ms = <MOUSE_SCROLL_DELAY>;
    acceleration-exponent = <MOUSE_SCROLL_ACCELERATION_EXPONENT>;
    time-to-max-speed-ms = <MOUSE_SCROLL_TIME_TO_MAXIMUM_SPEED>;
};
// ==== MOUSE-KEY <section ends> =====

/* Automatically generated keymap */
/ {
    keymap {
        compatible = "zmk,keymap";


        layer_Engrammer {
            display-name = "Engrammer";
            bindings = <
               &kp F1                           &kp F2                          &kp F3                           &kp F4                           &kp F5                                                                                                                                                                                                                                                                        &kp F6                            &kp F7                           &kp F8                            &kp F9               &kp F10
            &kp GRAVE                           &kp N1                          &kp N2                           &kp N3                           &kp N4                     &kp N5                                                                                                                                                                                                           &kp N6                            &kp N7                            &kp N8                           &kp N9                            &kp N0              &kp BSLH
            &kp EQUAL                            &kp B                           &kp Y                            &kp O                            &kp U                    &kp SQT                                                                                                                                                                                                         &kp SEMI                             &kp L                             &kp D                            &kp W                             &kp V                 &kp Z
           &caps_word  HOME_ROW_MOD(left_pinky) LEFT_PINKY_MOD C  HOME_ROW_MOD(left_ring) LEFT_RING_MOD I  HOME_ROW_MOD(left_middy) LEFT_MIDDY_MOD E  HOME_ROW_MOD(left_index) LEFT_INDEX_MOD A  &plain LAYER_Typing COMMA                                                                                                                                                                                          &plain LAYER_Typing DOT  HOME_ROW_MOD(right_index) RIGHT_INDEX_MOD H  HOME_ROW_MOD(right_middy) RIGHT_MIDDY_MOD T  HOME_ROW_MOD(right_ring) RIGHT_RING_MOD S  HOME_ROW_MOD(right_pinky) RIGHT_PINKY_MOD N                &q_btn
          &skq LSHIFT                            &kp G                           &kp X                            &kp J                            &kp K                  &kp MINUS      &thumb LAYER_Function ESC                                &kp UP                   &kp DOWN                &kp LEFT                            &kp RIGHT  &thumb LAYER_System ENTER                 &kp FSLH                             &kp R                             &kp M                            &kp F                             &kp P           &skq RSHIFT
 &magic LAYER_Magic 0                         &kp HOME                       &kp PG_UP                        &kp PG_DN                          &kp END                             &thumb LAYER_Cursor BACKSPACE  &thumb_lower_shift LAYER_Number LSFT  &thumb LAYER_Lower DELETE  &thumb LAYER_Lower TAB  &thumb_lower_shift LAYER_Mouse RSFT  &space LAYER_Symbol SPACE                                               &parang_left                          &kp LBKT                         &kp RBKT                     &parang_right  &magic LAYER_Magic 0
            >;
        };

        layer_HandsDown {
            display-name = "Hands Down";
            bindings = <
               &kp F1                           &kp F2                          &kp F3                           &kp F4                           &kp F5                                                                                                                                                                                                                                                                  &kp F6                            &kp F7                           &kp F8                            &kp F9               &kp F10
            &kp GRAVE                           &kp N1                          &kp N2                           &kp N3                           &kp N4                 &kp N5                                                                                                                                                                                                         &kp N6                            &kp N7                            &kp N8                           &kp N9                            &kp N0              &kp BSLH
            &kp EQUAL                            &kp W                           &kp F                            &kp M                            &kp P                  &kp V                                                                                                                                                                                                       &kp FSLH                           &kp DOT                            &q_btn                        &kp COMMA                           &kp SQT                 &kp Z
           &caps_word  HOME_ROW_MOD(left_pinky) LEFT_PINKY_MOD R  HOME_ROW_MOD(left_ring) LEFT_RING_MOD S  HOME_ROW_MOD(left_middy) LEFT_MIDDY_MOD N  HOME_ROW_MOD(left_index) LEFT_INDEX_MOD T  &plain LAYER_Typing B                                                                                                                                                                                      &plain LAYER_Typing COMMA  HOME_ROW_MOD(right_index) RIGHT_INDEX_MOD A  HOME_ROW_MOD(right_middy) RIGHT_MIDDY_MOD E  HOME_ROW_MOD(right_ring) RIGHT_RING_MOD I  HOME_ROW_MOD(right_pinky) RIGHT_PINKY_MOD H                 &kp J
          &skq LSHIFT                            &kp X                           &kp C                            &kp L                            &kp D                  &kp G  &thumb LAYER_Function ESC                                &kp UP                   &kp DOWN                &kp LEFT                            &kp RIGHT  &thumb LAYER_System ENTER                  &kp MINUS                             &kp U                             &kp O                            &kp Y                             &kp K           &skq RSHIFT
 &magic LAYER_Magic 0                         &kp HOME                       &kp PG_UP                        &kp PG_DN                          &kp END                             &thumb LAYER_Typing R  &thumb_lower_shift LAYER_Number LSFT  &thumb LAYER_Lower DELETE  &thumb LAYER_Lower TAB  &thumb_lower_shift LAYER_Mouse RSFT  &space LAYER_Symbol SPACE                                                 &parang_left                          &kp LBKT                         &kp RBKT                     &parang_right  &magic LAYER_Magic 0
            >;
        };

        layer_Apt {
            display-name = "APT";
            bindings = <
               &kp F1                     &kp F2                    &kp F3                     &kp F4                     &kp F5                                                                                                                                                                                                                                                            &kp F6                      &kp F7                     &kp F8                      &kp F9               &kp F10
            &kp GRAVE                     &kp N1                    &kp N2                     &kp N3                     &kp N4                 &kp N5                                                                                                                                                                                                         &kp N6                      &kp N7                      &kp N8                     &kp N9                      &kp N0              &kp BSLH
            &kp EQUAL                      &kp W                     &kp G                      &kp D                      &kp F                  &kp B                                                                                                                                                                                                         &q_btn                       &kp L                       &kp U                      &kp O                       &kp Y             &kp MINUS
           &caps_word  HOME_ROW_MOD(left_pinky) LEFT_PINKY_MOD R  HOME_ROW_MOD(left_ring) LEFT_RING_MOD S  HOME_ROW_MOD(left_middy) LEFT_MIDDY_MOD T  HOME_ROW_MOD(left_index) LEFT_INDEX_MOD H  &plain LAYER_Typing K                                                                                                                                                                                          &plain LAYER_Typing J  HOME_ROW_MOD(right_index) RIGHT_INDEX_MOD N  HOME_ROW_MOD(right_middy) RIGHT_MIDDY_MOD E  HOME_ROW_MOD(right_ring) RIGHT_RING_MOD A  HOME_ROW_MOD(right_pinky) RIGHT_PINKY_MOD I              &kp SEMI
          &skq LSHIFT                      &kp X                     &kp C                      &kp M                      &kp P                  &kp V      &thumb LAYER_Function ESC                                &kp UP                   &kp DOWN                &kp LEFT                            &kp RIGHT  &thumb LAYER_System ENTER                  &kp Z                   &kp COMMA                     &kp DOT                    &kp SQT                    &kp FSLH           &skq RSHIFT
 &magic LAYER_Magic 0                   &kp HOME                 &kp PG_UP                  &kp PG_DN                    &kp END                         &thumb LAYER_Cursor BACKSPACE  &thumb_lower_shift LAYER_Number LSFT  &thumb LAYER_Lower DELETE  &thumb LAYER_Lower TAB  &thumb_lower_shift LAYER_Mouse RSFT  &space LAYER_Symbol SPACE                                       &parang_left                    &kp LBKT                   &kp RBKT               &parang_right  &magic LAYER_Magic 0
            >;
        };

        layer_ColemakDHm {
            display-name = "Colemak-DHm";
            bindings = <
               &kp F1                            &kp F2                           &kp F3                            &kp F4                            &kp F5                                                                                                                                                                                                                                                                   &kp F6                             &kp F7                            &kp F8                             &kp F9               &kp F10
            &kp GRAVE                            &kp N1                           &kp N2                            &kp N3                            &kp N4                 &kp N5                                                                                                                                                                                                         &kp N6                             &kp N7                             &kp N8                            &kp N9                             &kp N0              &kp BSLH
            &kp EQUAL                            &q_btn                            &kp W                             &kp F                             &kp P                  &kp B                                                                                                                                                                                                          &kp J                              &kp L                              &kp U                             &kp Y                           &kp SEMI             &kp MINUS
           &caps_word  HOME_ROW_MOD(left_pinky) LEFT_PINKY_MOD A  HOME_ROW_MOD(left_ring) LEFT_RING_MOD R  HOME_ROW_MOD(left_middy) LEFT_MIDDY_MOD S  HOME_ROW_MOD(left_index) LEFT_INDEX_MOD T  &plain LAYER_Typing G                                                                                                                                                                                          &plain LAYER_Typing M  HOME_ROW_MOD(right_index) RIGHT_INDEX_MOD N  HOME_ROW_MOD(right_middy) RIGHT_MIDDY_MOD E  HOME_ROW_MOD(right_ring) RIGHT_RING_MOD I  HOME_ROW_MOD(right_pinky) RIGHT_PINKY_MOD O               &kp SQT
          &skq LSHIFT                             &kp Z                            &kp X                             &kp C                             &kp D                  &kp V      &thumb LAYER_Function ESC                                &kp UP                   &kp DOWN                &kp LEFT                            &kp RIGHT  &thumb LAYER_System ENTER                  &kp K                              &kp H                          &kp COMMA                           &kp DOT                           &kp FSLH           &skq RSHIFT
 &magic LAYER_Magic 0                          &kp HOME                        &kp PG_UP                         &kp PG_DN                           &kp END                         &thumb LAYER_Cursor BACKSPACE  &thumb_lower_shift LAYER_Number LSFT  &thumb LAYER_Lower DELETE  &thumb LAYER_Lower TAB  &thumb_lower_shift LAYER_Mouse RSFT  &space LAYER_Symbol SPACE                                              &parang_left                           &kp LBKT                          &kp RBKT                      &parang_right  &magic LAYER_Magic 0
            >;
        };

        layer_Colemak {
            display-name = "Colemak";
            bindings = <
               &kp F1                         &kp F2                        &kp F3                         &kp F4                         &kp F5                                                                                                                                                                                                                                                                &kp F6                          &kp F7                         &kp F8                          &kp F9               &kp F10
            &kp GRAVE                         &kp N1                        &kp N2                         &kp N3                         &kp N4                 &kp N5                                                                                                                                                                                                         &kp N6                          &kp N7                          &kp N8                         &kp N9                          &kp N0              &kp BSLH
            &kp EQUAL                         &q_btn                         &kp W                          &kp F                          &kp P                  &kp G                                                                                                                                                                                                          &kp J                           &kp L                           &kp U                          &kp Y                        &kp SEMI             &kp MINUS
           &caps_word  HOME_ROW_MOD(left_pinky) LEFT_PINKY_MOD A  HOME_ROW_MOD(left_ring) LEFT_RING_MOD R  HOME_ROW_MOD(left_middy) LEFT_MIDDY_MOD S  HOME_ROW_MOD(left_index) LEFT_INDEX_MOD T  &plain LAYER_Typing D                                                                                                                                                                                          &plain LAYER_Typing H  HOME_ROW_MOD(right_index) RIGHT_INDEX_MOD N  HOME_ROW_MOD(right_middy) RIGHT_MIDDY_MOD E  HOME_ROW_MOD(right_ring) RIGHT_RING_MOD I  HOME_ROW_MOD(right_pinky) RIGHT_PINKY_MOD O               &kp SQT
          &skq LSHIFT                          &kp Z                         &kp X                          &kp C                          &kp V                  &kp B      &thumb LAYER_Function ESC                                &kp UP                   &kp DOWN                &kp LEFT                            &kp RIGHT  &thumb LAYER_System ENTER                  &kp K                           &kp M                       &kp COMMA                        &kp DOT                        &kp FSLH           &skq RSHIFT
 &magic LAYER_Magic 0                       &kp HOME                     &kp PG_UP                      &kp PG_DN                        &kp END                         &thumb LAYER_Cursor BACKSPACE  &thumb_lower_shift LAYER_Number LSFT  &thumb LAYER_Lower DELETE  &thumb LAYER_Lower TAB  &thumb_lower_shift LAYER_Mouse RSFT  &space LAYER_Symbol SPACE                                           &parang_left                        &kp LBKT                       &kp RBKT                   &parang_right  &magic LAYER_Magic 0
            >;
        };

        layer_Norman {
            display-name = "Norman";
            bindings = <
               &kp F1                        &kp F2                       &kp F3                        &kp F4                        &kp F5                                                                                                                                                                                                                                                               &kp F6                         &kp F7                        &kp F8                         &kp F9               &kp F10
            &kp GRAVE                        &kp N1                       &kp N2                        &kp N3                        &kp N4                 &kp N5                                                                                                                                                                                                         &kp N6                         &kp N7                         &kp N8                        &kp N9                         &kp N0              &kp BSLH
            &kp EQUAL                        &q_btn                        &kp W                         &kp D                         &kp F                  &kp K                                                                                                                                                                                                          &kp J                          &kp U                          &kp R                         &kp L                       &kp SEMI             &kp MINUS
           &caps_word  HOME_ROW_MOD(left_pinky) LEFT_PINKY_MOD A  HOME_ROW_MOD(left_ring) LEFT_RING_MOD S  HOME_ROW_MOD(left_middy) LEFT_MIDDY_MOD E  HOME_ROW_MOD(left_index) LEFT_INDEX_MOD T  &plain LAYER_Typing G                                                                                                                                                                                          &plain LAYER_Typing Y  HOME_ROW_MOD(right_index) RIGHT_INDEX_MOD N  HOME_ROW_MOD(right_middy) RIGHT_MIDDY_MOD I  HOME_ROW_MOD(right_ring) RIGHT_RING_MOD O  HOME_ROW_MOD(right_pinky) RIGHT_PINKY_MOD H               &kp SQT
          &skq LSHIFT                         &kp Z                        &kp X                         &kp C                         &kp V                  &kp B      &thumb LAYER_Function ESC                                &kp UP                   &kp DOWN                &kp LEFT                            &kp RIGHT  &thumb LAYER_System ENTER                  &kp P                          &kp M                      &kp COMMA                       &kp DOT                       &kp FSLH           &skq RSHIFT
 &magic LAYER_Magic 0                      &kp HOME                    &kp PG_UP                     &kp PG_DN                       &kp END                         &thumb LAYER_Cursor BACKSPACE  &thumb_lower_shift LAYER_Number LSFT  &thumb LAYER_Lower DELETE  &thumb LAYER_Lower TAB  &thumb_lower_shift LAYER_Mouse RSFT  &space LAYER_Symbol SPACE                                          &parang_left                       &kp LBKT                      &kp RBKT                  &parang_right  &magic LAYER_Magic 0
            >;
        };

        layer_Workman {
            display-name = "Workman";
            bindings = <
               &kp F1                         &kp F2                        &kp F3                         &kp F4                         &kp F5                                                                                                                                                                                                                                                                &kp F6                          &kp F7                         &kp F8                          &kp F9               &kp F10
            &kp GRAVE                         &kp N1                        &kp N2                         &kp N3                         &kp N4                 &kp N5                                                                                                                                                                                                         &kp N6                          &kp N7                          &kp N8                         &kp N9                          &kp N0              &kp BSLH
            &kp EQUAL                         &q_btn                         &kp D                          &kp R                          &kp W                  &kp B                                                                                                                                                                                                          &kp J                           &kp F                           &kp U                          &kp P                        &kp SEMI             &kp MINUS
           &caps_word  HOME_ROW_MOD(left_pinky) LEFT_PINKY_MOD A  HOME_ROW_MOD(left_ring) LEFT_RING_MOD S  HOME_ROW_MOD(left_middy) LEFT_MIDDY_MOD H  HOME_ROW_MOD(left_index) LEFT_INDEX_MOD T  &plain LAYER_Typing G                                                                                                                                                                                          &plain LAYER_Typing Y  HOME_ROW_MOD(right_index) RIGHT_INDEX_MOD N  HOME_ROW_MOD(right_middy) RIGHT_MIDDY_MOD E  HOME_ROW_MOD(right_ring) RIGHT_RING_MOD O  HOME_ROW_MOD(right_pinky) RIGHT_PINKY_MOD I               &kp SQT
          &skq LSHIFT                          &kp Z                         &kp X                          &kp M                          &kp C                  &kp V      &thumb LAYER_Function ESC                                &kp UP                   &kp DOWN                &kp LEFT                            &kp RIGHT  &thumb LAYER_System ENTER                  &kp K                           &kp L                       &kp COMMA                        &kp DOT                        &kp FSLH           &skq RSHIFT
 &magic LAYER_Magic 0                       &kp HOME                     &kp PG_UP                      &kp PG_DN                        &kp END                         &thumb LAYER_Cursor BACKSPACE  &thumb_lower_shift LAYER_Number LSFT  &thumb LAYER_Lower DELETE  &thumb LAYER_Lower TAB  &thumb_lower_shift LAYER_Mouse RSFT  &space LAYER_Symbol SPACE                                           &parang_left                        &kp LBKT                       &kp RBKT                   &parang_right  &magic LAYER_Magic 0
            >;
        };

        layer_Halmak {
            display-name = "Halmak";
            bindings = <
               &kp F1                        &kp F2                       &kp F3                        &kp F4                        &kp F5                                                                                                                                                                                                                                                                     &kp F6                         &kp F7                        &kp F8                         &kp F9               &kp F10
            &kp GRAVE                        &kp N1                       &kp N2                        &kp N3                        &kp N4                     &kp N5                                                                                                                                                                                                           &kp N6                         &kp N7                         &kp N8                        &kp N9                         &kp N0              &kp BSLH
            &kp EQUAL                         &kp W                        &kp L                         &kp R                         &kp B                      &kp Z                                                                                                                                                                                                         &kp SEMI                         &q_btn                          &kp U                         &kp D                          &kp J             &kp MINUS
           &caps_word  HOME_ROW_MOD(left_pinky) LEFT_PINKY_MOD S  HOME_ROW_MOD(left_ring) LEFT_RING_MOD H  HOME_ROW_MOD(left_middy) LEFT_MIDDY_MOD N  HOME_ROW_MOD(left_index) LEFT_INDEX_MOD T  &plain LAYER_Typing COMMA                                                                                                                                                                                          &plain LAYER_Typing DOT  HOME_ROW_MOD(right_index) RIGHT_INDEX_MOD A  HOME_ROW_MOD(right_middy) RIGHT_MIDDY_MOD E  HOME_ROW_MOD(right_ring) RIGHT_RING_MOD O  HOME_ROW_MOD(right_pinky) RIGHT_PINKY_MOD I               &kp SQT
          &skq LSHIFT                         &kp F                        &kp M                         &kp V                         &kp C                   &kp FSLH      &thumb LAYER_Function ESC                                &kp UP                   &kp DOWN                &kp LEFT                            &kp RIGHT  &thumb LAYER_System ENTER                    &kp G                          &kp P                          &kp X                         &kp K                          &kp Y           &skq RSHIFT
 &magic LAYER_Magic 0                      &kp HOME                    &kp PG_UP                     &kp PG_DN                       &kp END                             &thumb LAYER_Cursor BACKSPACE  &thumb_lower_shift LAYER_Number LSFT  &thumb LAYER_Lower DELETE  &thumb LAYER_Lower TAB  &thumb_lower_shift LAYER_Mouse RSFT  &space LAYER_Symbol SPACE                                            &parang_left                       &kp LBKT                      &kp RBKT                  &parang_right  &magic LAYER_Magic 0
            >;
        };

        layer_Dvorak {
            display-name = "Dvorak";
            bindings = <
               &kp F1                        &kp F2                       &kp F3                        &kp F4                        &kp F5                                                                                                                                                                                                                                                               &kp F6                         &kp F7                        &kp F8                         &kp F9               &kp F10
            &kp GRAVE                        &kp N1                       &kp N2                        &kp N3                        &kp N4                 &kp N5                                                                                                                                                                                                         &kp N6                         &kp N7                         &kp N8                        &kp N9                         &kp N0              &kp BSLH
            &kp EQUAL                       &kp SQT                    &kp COMMA                       &kp DOT                         &kp P                  &kp Y                                                                                                                                                                                                          &kp F                          &kp G                          &kp C                         &kp R                          &kp L              &kp FSLH
           &caps_word  HOME_ROW_MOD(left_pinky) LEFT_PINKY_MOD A  HOME_ROW_MOD(left_ring) LEFT_RING_MOD O  HOME_ROW_MOD(left_middy) LEFT_MIDDY_MOD E  HOME_ROW_MOD(left_index) LEFT_INDEX_MOD U  &plain LAYER_Typing I                                                                                                                                                                                          &plain LAYER_Typing D  HOME_ROW_MOD(right_index) RIGHT_INDEX_MOD H  HOME_ROW_MOD(right_middy) RIGHT_MIDDY_MOD T  HOME_ROW_MOD(right_ring) RIGHT_RING_MOD N  HOME_ROW_MOD(right_pinky) RIGHT_PINKY_MOD S             &kp MINUS
          &skq LSHIFT                      &kp SEMI                       &q_btn                         &kp J                         &kp K                  &kp X      &thumb LAYER_Function ESC                                &kp UP                   &kp DOWN                &kp LEFT                            &kp RIGHT  &thumb LAYER_System ENTER                  &kp B                          &kp M                          &kp W                         &kp V                          &kp Z           &skq RSHIFT
 &magic LAYER_Magic 0                      &kp HOME                    &kp PG_UP                     &kp PG_DN                       &kp END                         &thumb LAYER_Cursor BACKSPACE  &thumb_lower_shift LAYER_Number LSFT  &thumb LAYER_Lower DELETE  &thumb LAYER_Lower TAB  &thumb_lower_shift LAYER_Mouse RSFT  &space LAYER_Symbol SPACE                                          &parang_left                       &kp LBKT                      &kp RBKT                  &parang_right  &magic LAYER_Magic 0
            >;
        };

        layer_Engram {
            display-name = "Engram";
            bindings = <
               &kp F1                        &kp F2                       &kp F3                        &kp F4                        &kp F5                                                                                                                                                                                                                                                                                       &kp F6                         &kp F7                        &kp F8                         &kp F9               &kp F10
             &kp LBKT                    &engram_N1                   &engram_N2                    &engram_N3                    &engram_N4                          &engram_N5                                                                                                                                                                                                                &engram_N6                     &engram_N7                     &engram_N8                    &engram_N9                     &engram_N0              &kp RBKT
           &engram_AT                         &kp B                        &kp Y                         &kp O                         &kp U                         &engram_SQT                                                                                                                                                                                                               &engram_DQT                          &kp L                          &kp D                         &kp W                          &kp V                 &kp Z
           &caps_word  HOME_ROW_MOD(left_pinky) LEFT_PINKY_MOD C  HOME_ROW_MOD(left_ring) LEFT_RING_MOD I  HOME_ROW_MOD(left_middy) LEFT_MIDDY_MOD E  HOME_ROW_MOD(left_index) LEFT_INDEX_MOD A  &plain_engram_COMMA LAYER_Typing 0                                                                                                                                                                                          &plain_engram_DOT LAYER_Typing 0  HOME_ROW_MOD(right_index) RIGHT_INDEX_MOD H  HOME_ROW_MOD(right_middy) RIGHT_MIDDY_MOD T  HOME_ROW_MOD(right_ring) RIGHT_RING_MOD S  HOME_ROW_MOD(right_pinky) RIGHT_PINKY_MOD N                &q_btn
          &skq LSHIFT                         &kp G                        &kp X                         &kp J                         &kp K                           &kp MINUS      &thumb LAYER_Function ESC                                &kp UP                   &kp DOWN                &kp LEFT                            &kp RIGHT  &thumb LAYER_System ENTER                     &engram_QMARK                          &kp R                          &kp M                         &kp F                          &kp P           &skq RSHIFT
 &magic LAYER_Magic 0                      &kp HOME                    &kp PG_UP                     &kp PG_DN                       &kp END                                      &thumb LAYER_Cursor BACKSPACE  &thumb_lower_shift LAYER_Number LSFT  &thumb LAYER_Lower DELETE  &thumb LAYER_Lower TAB  &thumb_lower_shift LAYER_Mouse RSFT  &space LAYER_Symbol SPACE                                                     &parang_left                   &engram_HASH                  &engram_FSLH                  &parang_right  &magic LAYER_Magic 0
            >;
        };

        layer_Typing {
            display-name = "Typing";
            bindings = <
 &trans              &trans             &trans              &trans              &trans                                                                                                                                                                                           &trans               &trans               &trans              &trans               &trans
 &trans              &trans             &trans              &trans              &trans         &trans                                                                                                                                                                            &trans               &trans               &trans              &trans               &trans  &trans
 &trans              &trans             &trans              &trans              &trans         &trans                                                                                                                                                                            &trans               &trans               &trans              &trans               &trans  &trans
 &trans  &kp LEFT_PINKY_KEY  &kp LEFT_RING_KEY  &kp LEFT_MIDDY_KEY  &kp LEFT_INDEX_KEY  &LeftPlainKey                                                                                                                                                                    &RightPlainKey  &kp RIGHT_INDEX_KEY  &kp RIGHT_MIDDY_KEY  &kp RIGHT_RING_KEY  &kp RIGHT_PINKY_KEY  &trans
 &trans              &trans             &trans              &trans              &trans         &trans  &kp KEY_LH_T1                             &trans         &trans         &trans                             &trans  &kp KEY_RH_T1          &trans               &trans               &trans              &trans               &trans  &trans
 &trans              &trans             &trans              &trans              &trans                 &kp KEY_LH_T4  &thumb_tog LAYER_Typing KEY_LH_T5  &kp KEY_LH_T6  &kp KEY_RH_T6  &thumb_tog LAYER_Typing KEY_LH_T5  &kp KEY_RH_T4                               &trans               &trans              &trans               &trans  &trans
            >;
        };

        layer_Cursor {
            display-name = "Cursor";
            bindings = <
     &none               &none              &none               &none               &none                                                                                                                             &none           &none           &none      &none        &none
   &kp ESC             &kp RET          &kp SPACE             &kp TAB             &kp DEL     &kp INS                                                                                                    &kp INS    &kp DEL         &kp TAB       &kp SPACE    &kp RET      &kp ESC
 &kp _C(K)           &sk LSHFT          &kp _REDO           &kp _UNDO            &kp BSPC    &kp _CUT                                                                                                   &kp _CUT   &kp BSPC       &kp _UNDO       &kp _REDO  &sk LSHFT    &kp _C(K)
 &kp _C(L)  &kp LEFT_PINKY_MOD  &kp LEFT_RING_MOD  &kp LEFT_MIDDY_MOD  &kp LEFT_INDEX_MOD   &kp _COPY                                                                                                  &kp _COPY   &kp LEFT          &kp UP        &kp DOWN  &kp RIGHT    &kp _C(L)
 &kp _C(J)           &kp _C(A)       &select_line        &select_word           &kp _FIND  &kp _PASTE  &mod_tab _A_TAB  &mod_tab _G_TAB            &kp TAB  &select_none  &extend_line  &extend_word  &kp _PASTE   &kp HOME       &kp PG_UP       &kp PG_DN    &kp END    &kp _C(J)
 &kp _C(H)      &kp _FIND_PREV       &extend_line        &extend_word      &kp _FIND_NEXT                        &none    &mod_tab LCTL  &tog LAYER_Cursor     &kp _C(A)  &select_line  &select_word              &kp _FIND  &kp _FIND_PREV  &kp _FIND_NEXT  &kp _C(H)  &kp LG(DOT)
            >;
        };

        layer_Number {
            display-name = "Number";
            bindings = <
      &none               &none              &none               &none               &none                                                                                                                &none       &none       &none          &none          &none
    &kp ESC             &kp RET          &kp SPACE             &kp TAB             &kp DEL  &kp INS                                                                                      &kp LS(N6)  &kp LS(N4)  &kp LS(N3)  &kp LS(N2)     &kp LS(N1)   &kp LS(BSLH)
      &none           &sk LSHFT          &kp _REDO           &kp _UNDO            &kp BSPC    &kp A                                                                                      &kp LS(N5)  &kp _KP_N7  &kp _KP_N8  &kp _KP_N9   &kp LS(SEMI)          &kp K
 &kp KP_NUM  &kp LEFT_PINKY_MOD  &kp LEFT_RING_MOD  &kp LEFT_MIDDY_MOD  &kp LEFT_INDEX_MOD    &kp B                                                                                    &kp _KP_PLUS  &kp _KP_N4  &kp _KP_N5  &kp _KP_N6  &kp _KP_MINUS          &kp J
      &none           &kp _C(A)       &select_line        &select_word       &kp LS(MINUS)    &kp C   &kp D   &kp E              &kp F  &kp LS(COMMA)  &kp LS(DOT)  &kp _KP_EQUAL  &kp _KP_ASTERISK  &kp _KP_N1  &kp _KP_N2  &kp _KP_N3  &kp _KP_SLASH      &kp LS(G)
      &none               &none       &extend_line        &extend_word               &kp X            &none   &none  &tog LAYER_Number  &kp _KP_COMMA  &kp _KP_DOT     &kp _KP_N0                        &trans      &trans      &trans         &trans  &kp LS(GRAVE)
            >;
        };

        layer_Function {
            display-name = "Function";
            bindings = <
    &none               &none              &none               &none               &none                                                                                                          &none             &none          &none         &none         &none
  &kp ESC             &kp RET          &kp SPACE             &kp TAB             &kp DEL                    &kp INS                                                                               &kp C_MEDIA_HOME  &kp C_PLAY     &kp C_PREV    &kp C_NEXT    &kp C_STOP     &kp C_EJECT
    &none           &sk LSHFT          &kp _REDO           &kp _UNDO            &kp BSPC                      &none                                                                               &kp K_WWW         &kp F3         &kp F6        &kp F9        &kp F12        &kp F15
 &kp CAPS  &kp LEFT_PINKY_MOD  &kp LEFT_RING_MOD  &kp LEFT_MIDDY_MOD  &kp LEFT_INDEX_MOD                      &none                                                                               &kp K_CALC        &kp F2         &kp F5        &kp F8        &kp F11        &kp F14
    &none           &kp _C(A)       &select_line        &select_word               &none    &kp SYS_MICROPHONE_MUTE   &none   &none                &none  &kp C_PREV  &kp C_NEXT    &kp C_PP      &kp C_AL_FILES    &kp F1         &kp F4        &kp F7        &kp F10        &kp F13
    &none               &none       &extend_line        &extend_word               &none                              &none   &none  &tog LAYER_Function  &kp C_MUTE  &kp C_VOL_DN  &kp C_VOL_UP                    &kp C_BRI_MAX  &kp C_BRI_UP  &kp C_BRI_DN  &kp C_BRI_MIN  &kp C_BRI_AUTO
            >;
        };

        layer_Symbol {
            display-name = "Symbol";
            bindings = <
         &none          &none         &none          &none          &none                                                                                                               &none                &none               &none                &none   &none
         &none      &kp GRAVE    &kp LS(N9)     &kp LS(N0)       &kp SEMI   &kp COMMA                                                                              &none                &none                &none               &none                &none   &none
    &kp LS(N1)   &kp LS(LBKT)       &kp SQT    &kp LS(SQT)   &kp LS(RBKT)   &kp QMARK                                                                           &kp SEMI  &kp RIGHT_INDEX_MOD  &kp RIGHT_MIDDY_MOD  &kp RIGHT_RING_MOD  &kp RIGHT_PINKY_MOD   &none
    &kp LS(N3)     &kp LS(N6)     &kp EQUAL  &kp LS(MINUS)     &kp LS(N4)  &kp LS(N8)                                                                            &kp DOT             &kp BSPC              &kp TAB           &kp SPACE              &kp RET   &none
    &kp LS(N2)  &kp LS(COMMA)  &kp LS(BSLH)      &kp MINUS    &kp LS(DOT)    &kp FSLH    &kp BSLH       &kp DOT  &kp LS(N8)              &none   &none   &none  &kp FSLH              &kp DEL          &kp LS(TAB)               &none                &none   &none
 &kp LS(GRAVE)     &kp LS(N7)      &kp LBKT       &kp RBKT  &kp LS(EQUAL)              &kp LS(N5)  &kp LS(SEMI)    &kp SEMI  &tog LAYER_Symbol   &none   &none                         &trans               &trans              &trans               &trans   &none
            >;
        };

        layer_Mouse {
            display-name = "Mouse";
            bindings = <
  &none   &none           &none           &none            &none                                                                                                   &none                &none               &none                &none   &none
  &none   &none           &none           &none            &none   &none                                                                      &none                &none                &none               &none                &none   &none
  &none   &none  &msc SCRL_LEFT    &mmv MOVE_UP  &msc SCRL_RIGHT   &none                                                                  &mkp MCLK  &kp RIGHT_INDEX_MOD  &kp RIGHT_MIDDY_MOD  &kp RIGHT_RING_MOD  &kp RIGHT_PINKY_MOD   &none
  &none   &none  &mmv MOVE_LEFT  &mmv MOVE_DOWN  &mmv MOVE_RIGHT   &none                                                                  &mkp LCLK       &mmv MOVE_LEFT         &mmv MOVE_UP      &mmv MOVE_DOWN      &mmv MOVE_RIGHT   &none
  &none   &none           &none  &msc SCRL_UP     &msc SCRL_DOWN   &none  &mkp MCLK      &none   &none             &none   &none   &none  &mkp RCLK       &msc SCRL_LEFT         &msc SCRL_UP      &msc SCRL_DOWN      &msc SCRL_RIGHT   &none
  &none   &none           &none           &none            &none          &mkp LCLK  &mkp RCLK   &none  &tog LAYER_Mouse   &none   &none                           &none                &none               &none                &none   &none
            >;
        };

        layer_System {
            display-name = "System";
            bindings = <
           &none            &none            &none            &none            &none                                                                                                                                 &none                &none               &none                &none            &none
           &none            &none            &none            &none            &none      &none                                                                                                 &none                &none                &none               &none                &none            &none
           &none            &none  &rgb_ug RGB_HUD  &rgb_ug RGB_HUI            &none      &none                                                                                       &rgb_ug RGB_SAI  &kp RIGHT_INDEX_MOD  &kp RIGHT_MIDDY_MOD  &kp RIGHT_RING_MOD  &kp RIGHT_PINKY_MOD  &rgb_ug RGB_SAD
 &rgb_ug RGB_TOG  &rgb_ug RGB_EFR  &rgb_ug RGB_BRD  &rgb_ug RGB_BRI  &rgb_ug RGB_EFF  &kp K_APP                                                                                       &rgb_ug RGB_HUI            &kp K_APP            &kp _LOCK          &kp _SLEEP           &kp _POWER  &rgb_ug RGB_HUD
           &none  &rgb_ug RGB_SPD  &rgb_ug RGB_SAD  &rgb_ug RGB_SAI  &rgb_ug RGB_SPI      &none  &kp _LOCK    &SLEEP           &POWER              &none   &none               &none  &rgb_ug RGB_SPI      &rgb_ug RGB_TOG            &kp PSCRN            &kp SLCK      &kp PAUSE_BREAK  &rgb_ug RGB_SPD
           &none            &none            &none            &none            &none             &kp PSCRN  &kp SLCK  &kp PAUSE_BREAK  &tog LAYER_System   &none  &linux_magic_sysrq                       &rgb_ug RGB_EFF      &rgb_ug RGB_BRI     &rgb_ug RGB_BRD      &rgb_ug RGB_EFR            &none
            >;
        };

        layer_Gaming {
            display-name = "Gaming";
            bindings = <
               &kp F1  &kp F2  &kp F3  &kp F4  &kp F5                                                                                                                                                       &kp F5  &kp F4  &kp F3  &kp F2  &kp F1
            &kp GRAVE  &kp N1  &kp N2  &kp N3  &kp N4  &kp N5                                                                                                                                       &kp N5  &kp N4  &kp N3  &kp N2  &kp N1  &kp GRAVE
            &kp EQUAL   &kp Q   &kp W   &kp E   &kp R   &kp T                                                                                                                                       &kp T   &kp R   &kp E   &kp W   &kp Q   &kp EQUAL
              &kp TAB   &kp A   &kp S   &kp D   &kp F   &kp G                                                                                                                                       &kp G   &kp S   &kp D   &kp F   &kp A   &kp TAB
                &kp M   &kp Z   &kp X   &kp C   &kp V   &kp B  &lt LAYER_GamingNumber ESC    &kp SPACE  &tto LAYER_Gaming ENTER  &tto LAYER_Gaming ENTER   &kp SPACE   &lt LAYER_GamingNumber ESC   &kp B   &kp V   &kp C   &kp X   &kp Z   &kp M
 &magic LAYER_Magic 0   &kp Y   &kp O   &kp N   &kp I                            &kp LALT   &kp LSHFT                &kp LCTRL  &kp LCTRL                 &kp LSHFT  &kp LALT                             &kp I   &kp O   &kp N   &kp Y   &magic LAYER_Magic 0
            >;
        };

        layer_GamingLeft {
            display-name = "Gaming Left";
            bindings = <
               &kp F1  &kp F2  &kp F3  &kp F4  &kp F5                                                                                                                                                             &kp F5  &kp F4  &kp F3  &kp F2  &kp F1
            &kp GRAVE  &kp N1  &kp N2  &kp N3  &kp N4  &kp N5                                                                                                                                             &kp N5  &kp N4  &kp N3  &kp N2  &kp N1  &kp GRAVE
            &kp EQUAL   &kp Q   &kp W   &kp E   &kp R   &kp T                                                                                                                                             &kp T   &kp R   &kp E   &kp W   &kp Q   &kp EQUAL
              &kp TAB   &kp A   &kp S   &kp D   &kp F   &kp G                                                                                                                                             &kp G   &kp F   &kp D   &kp S   &kp A   &kp TAB
                &kp M   &kp Z   &kp X   &kp C   &kp V   &kp B  &lt LAYER_GamingNumber ESC   &kp SPACE  &tto LAYER_GamingLeft ENTER  &tto LAYER_GamingLeft ENTER   &kp SPACE  &lt LAYER_GamingNumber ESC   &kp B   &kp V   &kp C   &kp X   &kp Z   &kp M
 &magic LAYER_Magic 0   &kp Y   &kp O   &kp N   &kp I                            &kp LALT  &kp LSHFT                    &kp LCTRL  &kp LCTRL                     &kp LALT &kp SPACE                             &kp I   &kp O   &kp N   &kp Y   &magic LAYER_Magic 0
            >;
        };

        layer_GamingNumber {
            display-name = "Gaming Number";
            bindings = <
              &kp F10        &kp F9     &kp F8     &kp F7     &kp F6                                                                                       &kp F6     &kp F7     &kp F8        &kp F9               &kp F10
             &kp BSPC        &kp N0     &kp N9     &kp N8     &kp N7  &kp N6                                                                    &kp N6     &kp N7     &kp N8     &kp N9        &kp N0              &kp BSPC
            &kp MINUS   &kp KP_PLUS  &kp KP_N9  &kp KP_N6  &kp KP_N3   &kp J                                                                     &kp J  &kp KP_N3  &kp KP_N6  &kp KP_N9   &kp KP_PLUS             &kp MINUS
             &kp FSLH  &kp KP_MINUS  &kp KP_N8  &kp KP_N5  &kp KP_N2   &kp P                                                                     &kp P  &kp KP_N2  &kp KP_N5  &kp KP_N8  &kp KP_MINUS              &kp FSLH
                &kp L     &kp KP_N0  &kp KP_N7  &kp KP_N4  &kp KP_N1   &kp U    &kp ESC   &kp SPACE    &kp RET    &kp RET   &kp SPACE    &kp ESC   &kp U  &kp KP_N1  &kp KP_N4  &kp KP_N7     &kp KP_N0                 &kp L
 &magic LAYER_Magic 0        &trans     &trans      &kp K      &kp H          &kp LALT  &kp LSHFT  &kp LCTRL  &kp LCTRL  &kp LSHFT  &kp LALT              &kp K      &kp H     &trans        &trans  &magic LAYER_Magic 0
            >;
        };

        layer_Factory {
            display-name = "Factory";
            bindings = <
               &kp F1    &kp F2   &kp F3    &kp F4     &kp F5                                                                                  &kp F6     &kp F7    &kp F8    &kp F9    &kp F10
            &kp EQUAL    &kp N1   &kp N2    &kp N3     &kp N4  &kp N5                                                                  &kp N6  &kp N7     &kp N8    &kp N9    &kp N0  &kp MINUS
              &kp TAB     &kp Q    &kp W     &kp E      &kp R   &kp T                                                                   &kp Y   &kp U      &kp I     &kp O     &kp P   &kp BSLH
              &kp ESC     &kp A    &kp S     &kp D      &kp F   &kp G                                                                   &kp H   &kp J      &kp K     &kp L  &kp SEMI    &kp SQT
            &kp GRAVE     &kp Z    &kp X     &kp C      &kp V   &kp B  &kp LSHFT  &kp LCTRL    &lower  &kp LGUI  &kp RCTRL  &kp RSHFT   &kp N   &kp M  &kp COMMA   &kp DOT  &kp FSLH  &kp PG_UP
 &magic LAYER_Magic 0  &kp HOME  &kp END  &kp LEFT  &kp RIGHT           &kp BSPC    &kp DEL  &kp LALT  &kp RALT    &kp RET  &kp SPACE          &kp UP   &kp DOWN  &kp LBKT  &kp RBKT  &kp PG_DN
            >;
        };

        layer_Lower {
            display-name = "Lower";
            bindings = <
         &kp C_BRI_DN     &kp C_BRI_UP      &kp C_PREV      &kp C_NEXT         &kp C_PP                                                                                                                                                 &kp C_MUTE  &kp C_VOL_DN  &kp C_VOL_UP            &none       &kp PAUSE_BREAK
            &kp EQUAL            &none           &none           &none            &none   &kp HOME                                                                                                                          &kp LS(N9)  &kp KP_NUM  &kp KP_EQUAL  &kp KP_SLASH  &kp KP_MULTIPLY       &kp PRINTSCREEN
              &kp TAB            &none           &none    &kp UP_ARROW            &none    &kp END                                                                                                                          &kp LS(N0)   &kp KP_N7     &kp KP_N8     &kp KP_N9     &kp KP_MINUS        &kp SCROLLLOCK
              &kp ESC            &none  &kp LEFT_ARROW  &kp DOWN_ARROW  &kp RIGHT_ARROW  &kp PG_UP                                                                                                                          &kp LS(N5)   &kp KP_N4     &kp KP_N5     &kp KP_N6      &kp KP_PLUS            &kp KP_NUM
            &kp GRAVE        &kp K_APP           &none         &kp F11          &kp F12  &kp PG_DN  &tog LAYER_Function  &tog LAYER_Typing  &tog LAYER_Gaming  &tog LAYER_GamingLeft  &tog LAYER_Typing  &tog LAYER_System   &kp COMMA   &kp KP_N1     &kp KP_N2     &kp KP_N3     &kp KP_ENTER              &kp CAPS
 &magic LAYER_Magic 0  &rgb_ug RGB_TOG         &kp INS        &kp LALT         &kp LGUI               &tog LAYER_Cursor  &tog LAYER_Number   &tog LAYER_Lower       &tog LAYER_Lower   &tog LAYER_Mouse  &tog LAYER_Symbol                &kp RGUI     &kp KP_N0    &kp KP_DOT     &kp KP_ENTER  &magic LAYER_Magic 0
            >;
        };

        layer_Magic {
            display-name = "Magic";
            bindings = <
  &bt BT_CLR            &none            &none            &none            &none                                                                                               &none   &none   &none   &none  &bt BT_CLR_ALL
       &to 0            &to 1            &to 2            &to 3            &to 4            &to 5                                                                      &to 6   &to 7   &to 8   &to 9   &none           &none
       &none  &rgb_ug RGB_SPI  &rgb_ug RGB_SAI  &rgb_ug RGB_HUI  &rgb_ug RGB_BRI  &rgb_ug RGB_TOG                                                                      &none   &none   &none   &none   &none           &none
 &bootloader  &rgb_ug RGB_SPD  &rgb_ug RGB_SAD  &rgb_ug RGB_HUD  &rgb_ug RGB_BRD  &rgb_ug RGB_EFF                                                                      &none   &none   &none   &none   &none     &bootloader
  &sys_reset            &none            &none            &none            &none            &none   &bt_2   &bt_3  &bt_4          &none                &none   &none   &none   &none   &none   &none   &none      &sys_reset
       &none            &none            &none            &none            &none                    &bt_0   &bt_1  &out OUT_USB   &studio_unlock   &tog LAYER_Factory   &none   &none           &none   &none   &none   &none           &none
            >;
        };

    };
};
